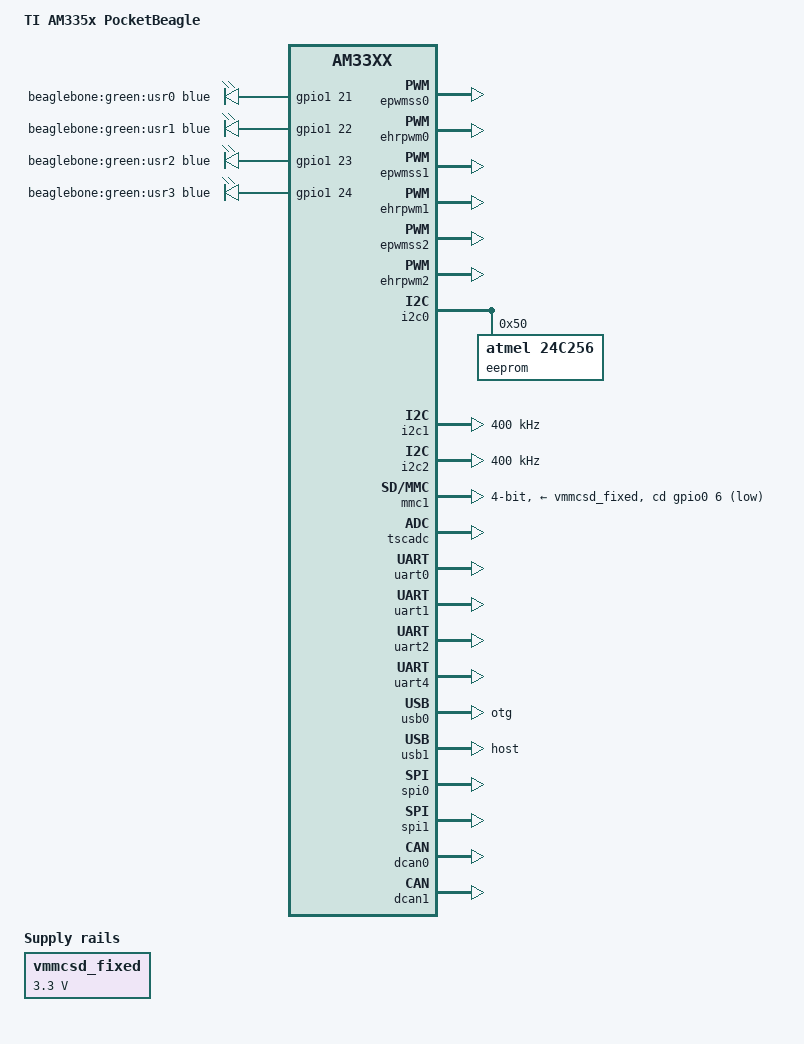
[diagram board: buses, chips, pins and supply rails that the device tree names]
// SPDX-License-Identifier: GPL-2.0
/*
 * Copyright (C) 2012 Texas Instruments Incorporated - https://www.ti.com/
 *
 * Author: Robert Nelson <robertcnelson@gmail.com>
 */
/dts-v1/;

#include "am33xx.dtsi"
#include "am335x-osd335x-common.dtsi"
#include <dt-bindings/leds/common.h>
#include <dt-bindings/board/am335x-bone-pins.h>

/ {
	model = "TI AM335x PocketBeagle";
	compatible = "ti,am335x-pocketbeagle", "ti,am335x-bone", "ti,am33xx";

	chosen {
		stdout-path = &uart0;
		base_dtb = "am335x-pocketbeagle.dts";
		base_dtb_timestamp = __TIMESTAMP__;
	};

	leds {
		pinctrl-names = "default";
		pinctrl-0 = <&usr_leds_pins>;

		compatible = "gpio-leds";

		led-usr0 {
			label = "beaglebone:green:usr0";
			color = <LED_COLOR_ID_BLUE>;
			function = LED_FUNCTION_HEARTBEAT;
			gpios = <&gpio1 21 GPIO_ACTIVE_HIGH>;
			linux,default-trigger = "heartbeat";
			default-state = "off";
		};

		led-usr1 {
			label = "beaglebone:green:usr1";
			color = <LED_COLOR_ID_BLUE>;
			function = LED_FUNCTION_DISK_ACTIVITY;
			gpios = <&gpio1 22 GPIO_ACTIVE_HIGH>;
			linux,default-trigger = "mmc0";
			default-state = "off";
		};

		led-usr2 {
			label = "beaglebone:green:usr2";
			color = <LED_COLOR_ID_BLUE>;
			function = LED_FUNCTION_CPU;
			gpios = <&gpio1 23 GPIO_ACTIVE_HIGH>;
			linux,default-trigger = "cpu0";
			default-state = "off";
		};

		led-usr3 {
			label = "beaglebone:green:usr3";
			color = <LED_COLOR_ID_BLUE>;
			function = LED_FUNCTION_INDICATOR;
			gpios = <&gpio1 24 GPIO_ACTIVE_HIGH>;
			default-state = "off";
		};
	};

	vmmcsd_fixed: fixedregulator0 {
		compatible = "regulator-fixed";
		regulator-name = "vmmcsd_fixed";
		regulator-min-microvolt = <3300000>;
		regulator-max-microvolt = <3300000>;
	};
};

&gpio0 {
	gpio-line-names =
		"NC",
		"NC",
		"P1.08 [SPI0_CLK]",
		"P1.10 [SPI0_MISO]",
		"P1.12 [SPI0_MOSI]",
		"P1.06 [SPI0_CS]",
		"[MMC0_CD]",
		"P2.29 [SPI1_CLK]",
		"[SYSBOOT 12]",
		"[SYSBOOT 13]",
		"[SYSBOOT 14]",
		"[SYSBOOT 15]",
		"P1.26 [I2C2_SDA]",
		"P1.28 [I2C2_SCL]",
		"P2.11 [I2C1_SDA]",
		"P2.09 [I2C1_SCL]",
		"NC",
		"NC",
		"NC",
		"P2.31 [SPI1_CS]",
		"P1.20 [PRU0.16]",
		"NC",
		"NC",
		"P2.03",
		"NC",
		"NC",
		"P1.34",
		"P2.19",
		"NC",
		"NC",
		"P2.05 [UART4_RX]",
		"P2.07 [UART4_TX]";
};

&gpio1 {
	gpio-line-names =
		"NC",
		"NC",
		"NC",
		"NC",
		"NC",
		"NC",
		"NC",
		"NC",
		"NC",
		"P2.25 [SPI1_MOSI]",
		"P1.32 [UART0_RX]",
		"P1.30 [UART0_TX]",
		"P2.24",
		"P2.33",
		"P2.22",
		"P2.18 [PRU0.15i]",
		"NC",
		"NC",
		"P2.01 [PWM1A]",
		"NC",
		"P2.10",
		"[USR LED 0]",
		"[USR LED 1]",
		"[USR LED 2]",
		"[USR LED 3]",
		"P2.06",
		"P2.04",
		"P2.02",
		"P2.08",
		"NC",
		"NC",
		"NC";
};

&gpio2 {
	gpio-line-names =
		"P2.20",
		"P2.17",
		"NC",
		"NC",
		"NC",
		"[EEPROM_WP]",
		"[SYSBOOT 0]",
		"[SYSBOOT 1]",
		"[SYSBOOT 2]",
		"[SYSBOOT 3]",
		"[SYSBOOT 4]",
		"[SYSBOOT 5]",
		"[SYSBOOT 6]",
		"[SYSBOOT 7]",
		"[SYSBOOT 8]",
		"[SYSBOOT 9]",
		"[SYSBOOT 10]",
		"[SYSBOOT 11]",
		"NC",
		"NC",
		"NC",
		"NC",
		"P2.35 [AIN5]",
		"P1.02 [AIN6]",
		"P1.35 [PRU1.10]",
		"P1.04 [PRU1.11]",
		"[MMC0_DAT3]",
		"[MMC0_DAT2]",
		"[MMC0_DAT1]",
		"[MMC0_DAT0]",
		"[MMC0_CLK]",
		"[MMC0_CMD]";
};

&gpio3 {
	gpio-line-names =
		"NC",
		"NC",
		"NC",
		"NC",
		"NC",
		"[I2C0_SDA]",
		"[I2C0_SCL]",
		"[JTAG EMU0]",
		"[JTAG EMU1]",
		"NC",
		"NC",
		"NC",
		"NC",
		"P1.03 [USB1]",
		"P1.36 [PWM0A]",
		"P1.33 [PRU0.1]",
		"P2.32 [PRU0.2]",
		"P2.30 [PRU0.3]",
		"P1.31 [PRU0.4]",
		"P2.34 [PRU0.5]",
		"P2.28 [PRU0.6]",
		"P1.29 [PRU0.7]",
		"NC",
		"NC",
		"NC",
		"NC",
		"NC",
		"NC",
		"NC",
		"NC",
		"NC",
		"NC";
};

&am33xx_pinmux {
//	i2c2_pins: pinmux-i2c2-pins {
//		pinctrl-single,pins = <
//			AM33XX_PADCONF(AM335X_PIN_UART1_RTSN, PIN_INPUT_PULLUP, MUX_MODE3)	/* (D17) uart1_rtsn.I2C2_SCL */
//			AM33XX_PADCONF(AM335X_PIN_UART1_CTSN, PIN_INPUT_PULLUP, MUX_MODE3)	/* (D18) uart1_ctsn.I2C2_SDA */
//		>;
//	};

//	ehrpwm0_pins: pinmux-ehrpwm0-pins {
//		pinctrl-single,pins = <
//			AM33XX_PADCONF(AM335X_PIN_MCASP0_ACLKX, PIN_OUTPUT_PULLDOWN, MUX_MODE1)	/* (A13) mcasp0_aclkx.ehrpwm0A */
//		>;
//	};

//	ehrpwm1_pins: pinmux-ehrpwm1-pins {
//		pinctrl-single,pins = <
//			AM33XX_PADCONF(AM335X_PIN_GPMC_A2, PIN_OUTPUT_PULLDOWN, MUX_MODE6)	/* (U14) gpmc_a2.ehrpwm1A */
//		>;
//	};

	mmc0_pins: pinmux-mmc0-pins {
		pinctrl-single,pins = <
			AM33XX_PADCONF(AM335X_PIN_SPI0_CS1, PIN_INPUT, MUX_MODE7)		/* (C15) spi0_cs1.gpio0[6] */
			AM33XX_PADCONF(AM335X_PIN_MMC0_DAT0, PIN_INPUT_PULLUP, MUX_MODE0)
			AM33XX_PADCONF(AM335X_PIN_MMC0_DAT1, PIN_INPUT_PULLUP, MUX_MODE0)
			AM33XX_PADCONF(AM335X_PIN_MMC0_DAT2, PIN_INPUT_PULLUP, MUX_MODE0)
			AM33XX_PADCONF(AM335X_PIN_MMC0_DAT3, PIN_INPUT_PULLUP, MUX_MODE0)
			AM33XX_PADCONF(AM335X_PIN_MMC0_CMD, PIN_INPUT_PULLUP, MUX_MODE0)
			AM33XX_PADCONF(AM335X_PIN_MMC0_CLK, PIN_INPUT_PULLUP, MUX_MODE0)
		>;
	};

//	spi0_pins: pinmux-spi0-pins {
//		pinctrl-single,pins = <
//			AM33XX_PADCONF(AM335X_PIN_SPI0_SCLK, PIN_INPUT_PULLUP, MUX_MODE0)	/* (A17) spi0_sclk.spi0_sclk */
//			AM33XX_PADCONF(AM335X_PIN_SPI0_D0, PIN_INPUT_PULLUP, MUX_MODE0)	/* (B17) spi0_d0.spi0_d0 */
//			AM33XX_PADCONF(AM335X_PIN_SPI0_D1, PIN_INPUT_PULLUP, MUX_MODE0)	/* (B16) spi0_d1.spi0_d1 */
//			AM33XX_PADCONF(AM335X_PIN_SPI0_CS0, PIN_INPUT_PULLUP, MUX_MODE0)	/* (A16) spi0_cs0.spi0_cs0 */
//		>;
//	};

//	spi1_pins: pinmux-spi1-pins {
//		pinctrl-single,pins = <
//			AM33XX_PADCONF(AM335X_PIN_ECAP0_IN_PWM0_OUT, PIN_INPUT_PULLUP, MUX_MODE4)	/* (C18) eCAP0_in_PWM0_out.spi1_sclk */
//			AM33XX_PADCONF(AM335X_PIN_UART0_CTSN, PIN_INPUT_PULLUP, MUX_MODE4)	/* (E18) uart0_ctsn.spi1_d0 */
//			AM33XX_PADCONF(AM335X_PIN_UART0_RTSN, PIN_INPUT_PULLUP, MUX_MODE4)	/* (E17) uart0_rtsn.spi1_d1 */
//			AM33XX_PADCONF(AM335X_PIN_XDMA_EVENT_INTR0, PIN_INPUT_PULLUP, MUX_MODE4)	/* (A15) xdma_event_intr0.spi1_cs1 */
//		>;
//	};

	usr_leds_pins: pinmux-usr-leds-pins {
		pinctrl-single,pins = <
			AM33XX_PADCONF(AM335X_PIN_GPMC_A5, PIN_OUTPUT, MUX_MODE7)		/* (V15) gpmc_a5.gpio1[21] - USR_LED_0 */
			AM33XX_PADCONF(AM335X_PIN_GPMC_A6, PIN_OUTPUT, MUX_MODE7)		/* (U15) gpmc_a6.gpio1[22] - USR_LED_1 */
			AM33XX_PADCONF(AM335X_PIN_GPMC_A7, PIN_OUTPUT, MUX_MODE7)		/* (T15) gpmc_a7.gpio1[23] - USR_LED_2 */
			AM33XX_PADCONF(AM335X_PIN_GPMC_A8, PIN_OUTPUT, MUX_MODE7)		/* (V16) gpmc_a8.gpio1[24] - USR_LED_3 */
		>;
	};

	uart0_pins: pinmux-uart0-pins {
		pinctrl-single,pins = <
			AM33XX_PADCONF(AM335X_PIN_UART0_RXD, PIN_INPUT_PULLUP, MUX_MODE0)
			AM33XX_PADCONF(AM335X_PIN_UART0_TXD, PIN_OUTPUT_PULLDOWN, MUX_MODE0)
		>;
	};

//	uart4_pins: pinmux-uart4-pins {
//		pinctrl-single,pins = <
//			AM33XX_PADCONF(AM335X_PIN_GPMC_WAIT0, PIN_INPUT_PULLUP, MUX_MODE6)	/* (T17) gpmc_wait0.uart4_rxd */
//			AM33XX_PADCONF(AM335X_PIN_GPMC_WPN, PIN_OUTPUT_PULLDOWN, MUX_MODE6)	/* (U17) gpmc_wpn.uart4_txd */
//		>;
//	};


/* macro: BONE_PIN( <pin>, <mode_name>, <register_value_macro(s)> */
#define BONE_PIN(XX,ZZ,QQ) \
	XX##_##ZZ##_pin: pinmux_##XX##_##ZZ##_pin { pinctrl-single,pins = < QQ >; };

	/************************/
	/* P1 Header */
	/************************/

	/* P1_01                VIN-AC */

	/* P1_02 (ZCZ ball R5) lcd_hsync (gpio2_23) */
	BONE_PIN(P1_02, default, P1_02(PIN_INPUT | MUX_MODE7))
	BONE_PIN(P1_02, gpio, P1_02(PIN_OUTPUT | INPUT_EN | MUX_MODE7))
	BONE_PIN(P1_02, gpio_pu, P1_02(PIN_OUTPUT_PULLUP | INPUT_EN | MUX_MODE7))
	BONE_PIN(P1_02, gpio_pd, P1_02(PIN_OUTPUT_PULLDOWN | INPUT_EN | MUX_MODE7))
	BONE_PIN(P1_02, pruout, P1_02(PIN_OUTPUT_PULLDOWN | INPUT_EN | MUX_MODE5))
	BONE_PIN(P1_02, pruin, P1_02(PIN_INPUT | MUX_MODE6))

	/* P1_03 (ZCZ ball F15)  usb1_vbus_out */

	/* P1_04 (ZCZ ball R6) lcd_ac_bias_en (gpio2_25) */
	BONE_PIN(P1_04, default, P1_04(PIN_OUTPUT_PULLDOWN | INPUT_EN | MUX_MODE7))
	BONE_PIN(P1_04, gpio, P1_04(PIN_OUTPUT | INPUT_EN | MUX_MODE7))
	BONE_PIN(P1_04, gpio_pu, P1_04(PIN_OUTPUT_PULLUP | INPUT_EN | MUX_MODE7))
	BONE_PIN(P1_04, gpio_pd, P1_04(PIN_OUTPUT_PULLDOWN | INPUT_EN | MUX_MODE7))
	BONE_PIN(P1_04, pruout, P1_04(PIN_OUTPUT_PULLDOWN | INPUT_EN | MUX_MODE5))
	BONE_PIN(P1_04, pruin, P1_04(PIN_INPUT | MUX_MODE6))

	/* P1_05 (ZCZ ball T18)  usb1_vbus_in */

	/* P1_06 (ZCZ ball A16) spi0_cs0 (spi0_cs0) */
	BONE_PIN(P1_06, default, P1_06(PIN_OUTPUT_PULLUP | INPUT_EN | MUX_MODE0))
	BONE_PIN(P1_06, gpio, P1_06(PIN_OUTPUT | INPUT_EN | MUX_MODE7))
	BONE_PIN(P1_06, gpio_pu, P1_06(PIN_OUTPUT_PULLUP | INPUT_EN | MUX_MODE7))
	BONE_PIN(P1_06, gpio_pd, P1_06(PIN_OUTPUT_PULLDOWN | INPUT_EN | MUX_MODE7))
	BONE_PIN(P1_06, spi_cs, P1_06(PIN_OUTPUT_PULLUP | INPUT_EN | MUX_MODE0))
	BONE_PIN(P1_06, i2c, P1_06(PIN_OUTPUT_PULLUP | INPUT_EN | MUX_MODE2))
	BONE_PIN(P1_06, pwm, P1_06(PIN_OUTPUT_PULLDOWN | INPUT_EN | MUX_MODE3))
	BONE_PIN(P1_06, pru_uart, P1_06(PIN_OUTPUT_PULLUP | INPUT_EN | MUX_MODE4))

	/* P1_07                VIN-USB */

	/* P1_08 (ZCZ ball A17) spi0_sclk (spi0_sclk) */
	BONE_PIN(P1_08, default, P1_08(PIN_OUTPUT_PULLUP | INPUT_EN | MUX_MODE0))
	BONE_PIN(P1_08, gpio, P1_08(PIN_OUTPUT | INPUT_EN | MUX_MODE7))
	BONE_PIN(P1_08, gpio_pu, P1_08(PIN_OUTPUT_PULLUP | INPUT_EN | MUX_MODE7))
	BONE_PIN(P1_08, gpio_pd, P1_08(PIN_OUTPUT_PULLDOWN | INPUT_EN | MUX_MODE7))
	BONE_PIN(P1_08, spi_sclk, P1_08(PIN_INPUT_PULLUP | MUX_MODE0))
	BONE_PIN(P1_08, uart, P1_08(PIN_OUTPUT_PULLUP | INPUT_EN | MUX_MODE1))
	BONE_PIN(P1_08, i2c, P1_08(PIN_OUTPUT_PULLUP | INPUT_EN | MUX_MODE2))
	BONE_PIN(P1_08, pwm, P1_08(PIN_OUTPUT_PULLDOWN | INPUT_EN | MUX_MODE3))
	BONE_PIN(P1_08, pru_uart, P1_08(PIN_OUTPUT_PULLUP | INPUT_EN | MUX_MODE4))

	/* P1_09 (ZCZ ball R18)  USB1-DN */

	/* P1_10 (ZCZ ball B17) spi0_d0 (spi0_d0) */
	BONE_PIN(P1_10, default, P1_10(PIN_OUTPUT_PULLUP | INPUT_EN | MUX_MODE0))
	BONE_PIN(P1_10, gpio, P1_10(PIN_OUTPUT | INPUT_EN | MUX_MODE7))
	BONE_PIN(P1_10, gpio_pu, P1_10(PIN_OUTPUT_PULLUP | INPUT_EN | MUX_MODE7))
	BONE_PIN(P1_10, gpio_pd, P1_10(PIN_OUTPUT_PULLDOWN | INPUT_EN | MUX_MODE7))
	BONE_PIN(P1_10, spi, P1_10(PIN_INPUT_PULLUP | MUX_MODE0))
	BONE_PIN(P1_10, uart, P1_10(PIN_OUTPUT_PULLUP | INPUT_EN | MUX_MODE1))
	BONE_PIN(P1_10, i2c, P1_10(PIN_OUTPUT_PULLUP | INPUT_EN | MUX_MODE2))
	BONE_PIN(P1_10, pwm, P1_10(PIN_OUTPUT_PULLDOWN | INPUT_EN | MUX_MODE3))
	BONE_PIN(P1_10, pru_uart, P1_10(PIN_OUTPUT_PULLUP | INPUT_EN | MUX_MODE4))

	/* P1_11 (ZCZ ball R17)  USB1-DP */

	/* P1_12 (ZCZ ball B16) spi0_d1 (spi0_d1) */
	BONE_PIN(P1_12, default, P1_12(PIN_OUTPUT_PULLUP | INPUT_EN | MUX_MODE0))
	BONE_PIN(P1_12, gpio, P1_12(PIN_OUTPUT | INPUT_EN | MUX_MODE7))
	BONE_PIN(P1_12, gpio_pu, P1_12(PIN_OUTPUT_PULLUP | INPUT_EN | MUX_MODE7))
	BONE_PIN(P1_12, gpio_pd, P1_12(PIN_OUTPUT_PULLDOWN | INPUT_EN | MUX_MODE7))
	BONE_PIN(P1_12, spi, P1_12(PIN_OUTPUT_PULLUP | INPUT_EN | MUX_MODE0))
	BONE_PIN(P1_12, i2c, P1_12(PIN_OUTPUT_PULLUP | INPUT_EN | MUX_MODE2))
	BONE_PIN(P1_12, pwm, P1_12(PIN_OUTPUT_PULLDOWN | INPUT_EN | MUX_MODE3))
	BONE_PIN(P1_12, pru_uart, P1_12(PIN_OUTPUT_PULLUP | INPUT_EN | MUX_MODE4))

	/* P1_13 (ZCZ ball P17)  USB1-ID */

	/* P1_14                VOUT-3.3V */

	/* P1_15                GND */

	/* P1_16                GND */

	/* P1_17 (ZCZ ball A9)  VREFN */

	/* P1_18 (ZCZ ball B9)  VREFP */

	/* P1_19 (ZCZ ball B6)  AIN0 */

	/* P1_20 (ZCZ ball D14) xdma_event_intr1 (gpio0_20) */
	BONE_PIN(P1_20, default, P1_20(PIN_OUTPUT_PULLDOWN | INPUT_EN | MUX_MODE7))
	BONE_PIN(P1_20, gpio, P1_20(PIN_OUTPUT | INPUT_EN | MUX_MODE7))
	BONE_PIN(P1_20, gpio_pu, P1_20(PIN_OUTPUT_PULLUP | INPUT_EN | MUX_MODE7))
	BONE_PIN(P1_20, gpio_pd, P1_20(PIN_OUTPUT_PULLDOWN | INPUT_EN | MUX_MODE7))
	BONE_PIN(P1_20, pruin, P1_20(PIN_INPUT | MUX_MODE5))

	/* P1_21 (ZCZ ball C7)  AIN1 */

	/* P1_22                GND */

	/* P1_23 (ZCZ ball B7)  AIN2 */

	/* P1_24                VOUT-5V */

	/* P1_25 (ZCZ ball A7)  AIN3 */

	/* P1_26 (ZCZ ball D18) uart1_ctsn (i2c2_sda) */
	BONE_PIN(P1_26, default, P1_26(PIN_OUTPUT_PULLUP | INPUT_EN | MUX_MODE3))
	BONE_PIN(P1_26, gpio, P1_26(PIN_OUTPUT | INPUT_EN | MUX_MODE7))
	BONE_PIN(P1_26, gpio_pu, P1_26(PIN_OUTPUT_PULLUP | INPUT_EN | MUX_MODE7))
	BONE_PIN(P1_26, gpio_pd, P1_26(PIN_OUTPUT_PULLDOWN | INPUT_EN | MUX_MODE7))
	BONE_PIN(P1_26, can, P1_26(PIN_OUTPUT_PULLUP | MUX_MODE2))
	BONE_PIN(P1_26, i2c, P1_26(PIN_OUTPUT_PULLUP | INPUT_EN | MUX_MODE3))
	BONE_PIN(P1_26, spi_cs, P1_26(PIN_OUTPUT_PULLUP | INPUT_EN | MUX_MODE4))
	BONE_PIN(P1_26, pru_uart, P1_26(PIN_OUTPUT_PULLUP | INPUT_EN | MUX_MODE5))

	/* P1_27 (ZCZ ball C8)  AIN4 */

	/* P1_28 (ZCZ ball D17) uart1_rtsn (i2c2_scl) */
	BONE_PIN(P1_28, default, P1_28(PIN_OUTPUT_PULLUP | INPUT_EN | MUX_MODE3))
	BONE_PIN(P1_28, gpio, P1_28(PIN_OUTPUT | INPUT_EN | MUX_MODE7))
	BONE_PIN(P1_28, gpio_pu, P1_28(PIN_OUTPUT_PULLUP | INPUT_EN | MUX_MODE7))
	BONE_PIN(P1_28, gpio_pd, P1_28(PIN_OUTPUT_PULLDOWN | INPUT_EN | MUX_MODE7))
	BONE_PIN(P1_28, can, P1_28(PIN_INPUT_PULLUP | MUX_MODE2))
	BONE_PIN(P1_28, i2c, P1_28(PIN_OUTPUT_PULLUP | INPUT_EN | MUX_MODE3))
	BONE_PIN(P1_28, spi_cs, P1_28(PIN_OUTPUT_PULLUP | INPUT_EN | MUX_MODE4))
	BONE_PIN(P1_28, pru_uart, P1_28(PIN_OUTPUT_PULLUP | INPUT_EN | MUX_MODE5))

	/* P1_29 (ZCZ ball A14) mcasp0_ahclkx (pru0_in7) */
	BONE_PIN(P1_29, default, P1_29(PIN_INPUT | MUX_MODE6))
	BONE_PIN(P1_29, gpio, P1_29(PIN_OUTPUT | INPUT_EN | MUX_MODE7))
	BONE_PIN(P1_29, gpio_pu, P1_29(PIN_OUTPUT_PULLUP | INPUT_EN | MUX_MODE7))
	BONE_PIN(P1_29, gpio_pd, P1_29(PIN_OUTPUT_PULLDOWN | INPUT_EN | MUX_MODE7))
	BONE_PIN(P1_29, eqep, P1_29(PIN_OUTPUT_PULLUP | INPUT_EN | MUX_MODE1))
	BONE_PIN(P1_29, pruout, P1_29(PIN_OUTPUT_PULLDOWN | INPUT_EN | MUX_MODE5))
	BONE_PIN(P1_29, pruin, P1_29(PIN_INPUT | MUX_MODE6))

	/* P1_30 (ZCZ ball E16) uart0_txd (uart0_txd) */
	BONE_PIN(P1_30, default, P1_30(PIN_OUTPUT_PULLUP | INPUT_EN | MUX_MODE0))
	BONE_PIN(P1_30, gpio, P1_30(PIN_OUTPUT | INPUT_EN | MUX_MODE7))
	BONE_PIN(P1_30, gpio_pu, P1_30(PIN_OUTPUT_PULLUP | INPUT_EN | MUX_MODE7))
	BONE_PIN(P1_30, gpio_pd, P1_30(PIN_OUTPUT_PULLDOWN | INPUT_EN | MUX_MODE7))
	BONE_PIN(P1_30, uart, P1_30(PIN_OUTPUT_PULLUP | INPUT_EN | MUX_MODE0))
	BONE_PIN(P1_30, spi_cs, P1_30(PIN_OUTPUT_PULLUP | INPUT_EN | MUX_MODE1))
	BONE_PIN(P1_30, can, P1_30(PIN_INPUT_PULLUP | MUX_MODE2))
	BONE_PIN(P1_30, i2c, P1_30(PIN_OUTPUT_PULLUP | INPUT_EN | MUX_MODE3))
	BONE_PIN(P1_30, pruout, P1_30(PIN_OUTPUT_PULLDOWN | INPUT_EN | MUX_MODE5))
	BONE_PIN(P1_30, pruin, P1_30(PIN_INPUT | MUX_MODE6))

	/* P1_31 (ZCZ ball B12) mcasp0_aclkr (pru0_in4) */
	BONE_PIN(P1_31, default, P1_31(PIN_INPUT | MUX_MODE6))
	BONE_PIN(P1_31, gpio, P1_31(PIN_OUTPUT | INPUT_EN | MUX_MODE7))
	BONE_PIN(P1_31, gpio_pu, P1_31(PIN_OUTPUT_PULLUP | INPUT_EN | MUX_MODE7))
	BONE_PIN(P1_31, gpio_pd, P1_31(PIN_OUTPUT_PULLDOWN | INPUT_EN | MUX_MODE7))
	BONE_PIN(P1_31, eqep, P1_31(PIN_OUTPUT_PULLUP | INPUT_EN | MUX_MODE1))
	BONE_PIN(P1_31, pruout, P1_31(PIN_OUTPUT_PULLDOWN | INPUT_EN | MUX_MODE5))
	BONE_PIN(P1_31, pruin, P1_31(PIN_INPUT | MUX_MODE6))

	/* P1_32 (ZCZ ball E15) uart0_rxd (uart0_rxd) */
	BONE_PIN(P1_32, default, P1_32(PIN_OUTPUT_PULLUP | INPUT_EN | MUX_MODE0))
	BONE_PIN(P1_32, gpio, P1_32(PIN_OUTPUT | INPUT_EN | MUX_MODE7))
	BONE_PIN(P1_32, gpio_pu, P1_32(PIN_OUTPUT_PULLUP | INPUT_EN | MUX_MODE7))
	BONE_PIN(P1_32, gpio_pd, P1_32(PIN_OUTPUT_PULLDOWN | INPUT_EN | MUX_MODE7))
	BONE_PIN(P1_32, uart, P1_32(PIN_OUTPUT_PULLUP | INPUT_EN | MUX_MODE0))
	BONE_PIN(P1_32, spi_cs, P1_32(PIN_OUTPUT_PULLUP | INPUT_EN | MUX_MODE1))
	BONE_PIN(P1_32, can, P1_32(PIN_OUTPUT_PULLUP | MUX_MODE2))
	BONE_PIN(P1_32, i2c, P1_32(PIN_OUTPUT_PULLUP | INPUT_EN | MUX_MODE3))
	BONE_PIN(P1_32, pruout, P1_32(PIN_OUTPUT_PULLDOWN | INPUT_EN | MUX_MODE5))
	BONE_PIN(P1_32, pruin, P1_32(PIN_INPUT | MUX_MODE6))

	/* P1_33 (ZCZ ball B13) mcasp0_fsx (pru0_in1) */
	BONE_PIN(P1_33, default, P1_33(PIN_INPUT | MUX_MODE6))
	BONE_PIN(P1_33, gpio, P1_33(PIN_OUTPUT | INPUT_EN | MUX_MODE7))
	BONE_PIN(P1_33, gpio_pu, P1_33(PIN_OUTPUT_PULLUP | INPUT_EN | MUX_MODE7))
	BONE_PIN(P1_33, gpio_pd, P1_33(PIN_OUTPUT_PULLDOWN | INPUT_EN | MUX_MODE7))
	BONE_PIN(P1_33, pwm, P1_33(PIN_OUTPUT_PULLDOWN | INPUT_EN | MUX_MODE1))
	BONE_PIN(P1_33, spi, P1_33(PIN_INPUT_PULLUP | MUX_MODE3))
	BONE_PIN(P1_33, pruout, P1_33(PIN_OUTPUT_PULLDOWN | INPUT_EN | MUX_MODE5))
	BONE_PIN(P1_33, pruin, P1_33(PIN_INPUT | MUX_MODE6))

	/* P1_34 (ZCZ ball T11) gpmc_ad10 (gpio0_26) */
	BONE_PIN(P1_34, default, P1_34(PIN_OUTPUT_PULLDOWN | INPUT_EN | MUX_MODE7))
	BONE_PIN(P1_34, gpio, P1_34(PIN_OUTPUT | INPUT_EN | MUX_MODE7))
	BONE_PIN(P1_34, gpio_pu, P1_34(PIN_OUTPUT_PULLUP | INPUT_EN | MUX_MODE7))
	BONE_PIN(P1_34, gpio_pd, P1_34(PIN_OUTPUT_PULLDOWN | INPUT_EN | MUX_MODE7))
	BONE_PIN(P1_34, pwm, P1_34(PIN_OUTPUT_PULLDOWN | INPUT_EN | MUX_MODE4))

	/* P1_35 (ZCZ ball V5) lcd_pclk (pru1_in10) */
	BONE_PIN(P1_35, default, P1_35(PIN_INPUT | MUX_MODE6))
	BONE_PIN(P1_35, gpio, P1_35(PIN_OUTPUT | INPUT_EN | MUX_MODE7))
	BONE_PIN(P1_35, gpio_pu, P1_35(PIN_OUTPUT_PULLUP | INPUT_EN | MUX_MODE7))
	BONE_PIN(P1_35, gpio_pd, P1_35(PIN_OUTPUT_PULLDOWN | INPUT_EN | MUX_MODE7))
	BONE_PIN(P1_35, pruout, P1_35(PIN_OUTPUT_PULLDOWN | INPUT_EN | MUX_MODE5))
	BONE_PIN(P1_35, pruin, P1_35(PIN_INPUT | MUX_MODE6))

	/* P1_36 (ZCZ ball A13) mcasp0_aclkx (ehrpwm0a) */
	BONE_PIN(P1_36, default, P1_36(PIN_OUTPUT_PULLDOWN | INPUT_EN | MUX_MODE1))
	BONE_PIN(P1_36, gpio, P1_36(PIN_OUTPUT | INPUT_EN | MUX_MODE7))
	BONE_PIN(P1_36, gpio_pu, P1_36(PIN_OUTPUT_PULLUP | INPUT_EN | MUX_MODE7))
	BONE_PIN(P1_36, gpio_pd, P1_36(PIN_OUTPUT_PULLDOWN | INPUT_EN | MUX_MODE7))
	BONE_PIN(P1_36, pwm, P1_36(PIN_OUTPUT_PULLDOWN | INPUT_EN | MUX_MODE1))
	BONE_PIN(P1_36, spi_sclk, P1_36(PIN_INPUT_PULLUP | MUX_MODE3))
	BONE_PIN(P1_36, pruout, P1_36(PIN_OUTPUT_PULLDOWN | INPUT_EN | MUX_MODE5))
	BONE_PIN(P1_36, pruin, P1_36(PIN_INPUT | MUX_MODE6))


	/************************/
	/* P2 Header */
	/************************/

	/* P2_01 (ZCZ ball U14) gpmc_a2 (ehrpwm1a) */
	BONE_PIN(P2_01, default, P2_01(PIN_OUTPUT_PULLDOWN | INPUT_EN | MUX_MODE6))
	BONE_PIN(P2_01, gpio, P2_01(PIN_OUTPUT | INPUT_EN | MUX_MODE7))
	BONE_PIN(P2_01, gpio_pu, P2_01(PIN_OUTPUT_PULLUP | INPUT_EN | MUX_MODE7))
	BONE_PIN(P2_01, gpio_pd, P2_01(PIN_OUTPUT_PULLDOWN | INPUT_EN | MUX_MODE7))
	BONE_PIN(P2_01, pwm, P2_01(PIN_OUTPUT_PULLDOWN | INPUT_EN | MUX_MODE6))

	/* P2_02 (ZCZ ball V17) gpmc_a11 (gpio1_27) */
	BONE_PIN(P2_02, default, P2_02(PIN_OUTPUT_PULLDOWN | INPUT_EN | MUX_MODE7))
	BONE_PIN(P2_02, gpio, P2_02(PIN_OUTPUT | INPUT_EN | MUX_MODE7))
	BONE_PIN(P2_02, gpio_pu, P2_02(PIN_OUTPUT_PULLUP | INPUT_EN | MUX_MODE7))
	BONE_PIN(P2_02, gpio_pd, P2_02(PIN_OUTPUT_PULLDOWN | INPUT_EN | MUX_MODE7))

	/* P2_03 (ZCZ ball T10) gpmc_ad9 (gpio0_23) */
	BONE_PIN(P2_03, default, P2_03(PIN_OUTPUT_PULLDOWN | INPUT_EN | MUX_MODE7))
	BONE_PIN(P2_03, gpio, P2_03(PIN_OUTPUT | INPUT_EN | MUX_MODE7))
	BONE_PIN(P2_03, gpio_pu, P2_03(PIN_OUTPUT_PULLUP | INPUT_EN | MUX_MODE7))
	BONE_PIN(P2_03, gpio_pd, P2_03(PIN_OUTPUT_PULLDOWN | INPUT_EN | MUX_MODE7))
	BONE_PIN(P2_03, pwm, P2_03(PIN_OUTPUT_PULLDOWN | INPUT_EN | MUX_MODE4))

	/* P2_04 (ZCZ ball T16) gpmc_a10 (gpio1_26) */
	BONE_PIN(P2_04, default, P2_04(PIN_OUTPUT_PULLDOWN | INPUT_EN | MUX_MODE7))
	BONE_PIN(P2_04, gpio, P2_04(PIN_OUTPUT | INPUT_EN | MUX_MODE7))
	BONE_PIN(P2_04, gpio_pu, P2_04(PIN_OUTPUT_PULLUP | INPUT_EN | MUX_MODE7))
	BONE_PIN(P2_04, gpio_pd, P2_04(PIN_OUTPUT_PULLDOWN | INPUT_EN | MUX_MODE7))

	/* P2_05 (ZCZ ball T17) gpmc_wait0 (uart4_rxd) */
	BONE_PIN(P2_05, default, P2_05(PIN_OUTPUT_PULLUP | INPUT_EN | MUX_MODE6))
	BONE_PIN(P2_05, gpio, P2_05(PIN_OUTPUT | INPUT_EN | MUX_MODE7))
	BONE_PIN(P2_05, gpio_pu, P2_05(PIN_OUTPUT_PULLUP | INPUT_EN | MUX_MODE7))
	BONE_PIN(P2_05, gpio_pd, P2_05(PIN_OUTPUT_PULLDOWN | INPUT_EN | MUX_MODE7))
	BONE_PIN(P2_05, uart, P2_05(PIN_OUTPUT_PULLUP | INPUT_EN | MUX_MODE6))

	/* P2_06 (ZCZ ball U16) gpmc_a9 (gpio1_25) */
	BONE_PIN(P2_06, default, P2_06(PIN_OUTPUT_PULLDOWN | INPUT_EN | MUX_MODE7))
	BONE_PIN(P2_06, gpio, P2_06(PIN_OUTPUT | INPUT_EN | MUX_MODE7))
	BONE_PIN(P2_06, gpio_pu, P2_06(PIN_OUTPUT_PULLUP | INPUT_EN | MUX_MODE7))
	BONE_PIN(P2_06, gpio_pd, P2_06(PIN_OUTPUT_PULLDOWN | INPUT_EN | MUX_MODE7))

	/* P2_07 (ZCZ ball U17) gpmc_wpn (uart4_txd) */
	BONE_PIN(P2_07, default, P2_07(PIN_OUTPUT_PULLUP | INPUT_EN | MUX_MODE6))
	BONE_PIN(P2_07, gpio, P2_07(PIN_OUTPUT | INPUT_EN | MUX_MODE7))
	BONE_PIN(P2_07, gpio_pu, P2_07(PIN_OUTPUT_PULLUP | INPUT_EN | MUX_MODE7))
	BONE_PIN(P2_07, gpio_pd, P2_07(PIN_OUTPUT_PULLDOWN | INPUT_EN | MUX_MODE7))
	BONE_PIN(P2_07, uart, P2_07(PIN_OUTPUT_PULLUP | INPUT_EN | MUX_MODE6))

	/* P2_08 (ZCZ ball U18) gpmc_be1n (gpio1_28) */
	BONE_PIN(P2_08, default, P2_08(PIN_OUTPUT_PULLUP | INPUT_EN | MUX_MODE7))
	BONE_PIN(P2_08, gpio, P2_08(PIN_OUTPUT | INPUT_EN | MUX_MODE7))
	BONE_PIN(P2_08, gpio_pu, P2_08(PIN_OUTPUT_PULLUP | INPUT_EN | MUX_MODE7))
	BONE_PIN(P2_08, gpio_pd, P2_08(PIN_OUTPUT_PULLDOWN | INPUT_EN | MUX_MODE7))

	/* P2_09 (ZCZ ball D15) uart1_txd (i2c1_scl) */
	BONE_PIN(P2_09, default, P2_09(PIN_OUTPUT_PULLUP | INPUT_EN | MUX_MODE3))
	BONE_PIN(P2_09, gpio, P2_09(PIN_OUTPUT | INPUT_EN | MUX_MODE7))
	BONE_PIN(P2_09, gpio_pu, P2_09(PIN_OUTPUT_PULLUP | INPUT_EN | MUX_MODE7))
	BONE_PIN(P2_09, gpio_pd, P2_09(PIN_OUTPUT_PULLDOWN | INPUT_EN | MUX_MODE7))
	BONE_PIN(P2_09, uart, P2_09(PIN_OUTPUT_PULLUP | INPUT_EN | MUX_MODE0))
	BONE_PIN(P2_09, can, P2_09(PIN_INPUT_PULLUP | MUX_MODE2))
	BONE_PIN(P2_09, i2c, P2_09(PIN_OUTPUT_PULLUP | INPUT_EN | MUX_MODE3))
	BONE_PIN(P2_09, pru_uart, P2_09(PIN_OUTPUT_PULLUP | INPUT_EN | MUX_MODE5))
	BONE_PIN(P2_09, pruin, P2_09(PIN_INPUT | MUX_MODE6))

	/* P2_10 (ZCZ ball R14) gpmc_a4 (gpio1_20) */
	BONE_PIN(P2_10, default, P2_10(PIN_OUTPUT_PULLDOWN | INPUT_EN | MUX_MODE7))
	BONE_PIN(P2_10, gpio, P2_10(PIN_OUTPUT | INPUT_EN | MUX_MODE7))
	BONE_PIN(P2_10, gpio_pu, P2_10(PIN_OUTPUT_PULLUP | INPUT_EN | MUX_MODE7))
	BONE_PIN(P2_10, gpio_pd, P2_10(PIN_OUTPUT_PULLDOWN | INPUT_EN | MUX_MODE7))
	BONE_PIN(P2_10, eqep, P2_10(PIN_OUTPUT_PULLUP | INPUT_EN | MUX_MODE6))

	/* P2_11 (ZCZ ball D16) uart1_rxd (i2c1_sda) */
	BONE_PIN(P2_11, default, P2_11(PIN_OUTPUT_PULLUP | INPUT_EN | MUX_MODE3))
	BONE_PIN(P2_11, gpio, P2_11(PIN_OUTPUT | INPUT_EN | MUX_MODE7))
	BONE_PIN(P2_11, gpio_pu, P2_11(PIN_OUTPUT_PULLUP | INPUT_EN | MUX_MODE7))
	BONE_PIN(P2_11, gpio_pd, P2_11(PIN_OUTPUT_PULLDOWN | INPUT_EN | MUX_MODE7))
	BONE_PIN(P2_11, uart, P2_11(PIN_OUTPUT_PULLUP | INPUT_EN | MUX_MODE0))
	BONE_PIN(P2_11, can, P2_11(PIN_OUTPUT_PULLUP | MUX_MODE2))
	BONE_PIN(P2_11, i2c, P2_11(PIN_OUTPUT_PULLUP | INPUT_EN | MUX_MODE3))
	BONE_PIN(P2_11, pru_uart, P2_11(PIN_OUTPUT_PULLUP | INPUT_EN | MUX_MODE5))
	BONE_PIN(P2_11, pruin, P2_11(PIN_INPUT | MUX_MODE6))

	/* P2_12                POWER_BUTTON */

	/* P2_13                VOUT-5V */

	/* P2_14                BAT-VIN */

	/* P2_15                GND */

	/* P2_16                BAT-TEMP */

	/* P2_17 (ZCZ ball V12) gpmc_clk (gpio2_1) */
	BONE_PIN(P2_17, default, P2_17(PIN_OUTPUT_PULLDOWN | INPUT_EN | MUX_MODE7))
	BONE_PIN(P2_17, gpio, P2_17(PIN_OUTPUT | INPUT_EN | MUX_MODE7))
	BONE_PIN(P2_17, gpio_pu, P2_17(PIN_OUTPUT_PULLUP | INPUT_EN | MUX_MODE7))
	BONE_PIN(P2_17, gpio_pd, P2_17(PIN_OUTPUT_PULLDOWN | INPUT_EN | MUX_MODE7))

	/* P2_18 (ZCZ ball U13) gpmc_ad15 (gpio1_15) */
	BONE_PIN(P2_18, default, P2_18(PIN_OUTPUT_PULLDOWN | INPUT_EN | MUX_MODE7))
	BONE_PIN(P2_18, gpio, P2_18(PIN_OUTPUT | INPUT_EN | MUX_MODE7))
	BONE_PIN(P2_18, gpio_pu, P2_18(PIN_OUTPUT_PULLUP | INPUT_EN | MUX_MODE7))
	BONE_PIN(P2_18, gpio_pd, P2_18(PIN_OUTPUT_PULLDOWN | INPUT_EN | MUX_MODE7))
	BONE_PIN(P2_18, eqep, P2_18(PIN_OUTPUT_PULLUP | INPUT_EN | MUX_MODE4))
	BONE_PIN(P2_18, pru_ecap_pwm, P2_18(PIN_OUTPUT_PULLDOWN | INPUT_EN | MUX_MODE5))
	BONE_PIN(P2_18, pruin, P2_18(PIN_INPUT | MUX_MODE6))

	/* P2_19 (ZCZ ball U12) gpmc_ad11 (gpio0_27) */
	BONE_PIN(P2_19, default, P2_19(PIN_OUTPUT_PULLDOWN | INPUT_EN | MUX_MODE7))
	BONE_PIN(P2_19, gpio, P2_19(PIN_OUTPUT | INPUT_EN | MUX_MODE7))
	BONE_PIN(P2_19, gpio_pu, P2_19(PIN_OUTPUT_PULLUP | INPUT_EN | MUX_MODE7))
	BONE_PIN(P2_19, gpio_pd, P2_19(PIN_OUTPUT_PULLDOWN | INPUT_EN | MUX_MODE7))
	BONE_PIN(P2_19, pwm, P2_19(PIN_OUTPUT_PULLDOWN | INPUT_EN | MUX_MODE4))

	/* P2_20 (ZCZ ball T13) gpmc_csn3 (gpio2_0) */
	BONE_PIN(P2_20, default, P2_20(PIN_OUTPUT_PULLUP | INPUT_EN | MUX_MODE7))
	BONE_PIN(P2_20, gpio, P2_20(PIN_OUTPUT | INPUT_EN | MUX_MODE7))
	BONE_PIN(P2_20, gpio_pu, P2_20(PIN_OUTPUT_PULLUP | INPUT_EN | MUX_MODE7))
	BONE_PIN(P2_20, gpio_pd, P2_20(PIN_OUTPUT_PULLDOWN | INPUT_EN | MUX_MODE7))

	/* P2_21                GND */

	/* P2_22 (ZCZ ball V13) gpmc_ad14 (gpio1_14) */
	BONE_PIN(P2_22, default, P2_22(PIN_OUTPUT_PULLDOWN | INPUT_EN | MUX_MODE7))
	BONE_PIN(P2_22, gpio, P2_22(PIN_OUTPUT | INPUT_EN | MUX_MODE7))
	BONE_PIN(P2_22, gpio_pu, P2_22(PIN_OUTPUT_PULLUP | INPUT_EN | MUX_MODE7))
	BONE_PIN(P2_22, gpio_pd, P2_22(PIN_OUTPUT_PULLDOWN | INPUT_EN | MUX_MODE7))
	BONE_PIN(P2_22, eqep, P2_22(PIN_OUTPUT_PULLUP | INPUT_EN | MUX_MODE4))
	BONE_PIN(P2_22, pruin, P2_22(PIN_INPUT | MUX_MODE6))

	/* P2_23                VOUT-3.3V */

	/* P2_24 (ZCZ ball T12) gpmc_ad12 (gpio1_12) */
	BONE_PIN(P2_24, default, P2_24(PIN_OUTPUT_PULLDOWN | INPUT_EN | MUX_MODE7))
	BONE_PIN(P2_24, gpio, P2_24(PIN_OUTPUT | INPUT_EN | MUX_MODE7))
	BONE_PIN(P2_24, gpio_pu, P2_24(PIN_OUTPUT_PULLUP | INPUT_EN | MUX_MODE7))
	BONE_PIN(P2_24, gpio_pd, P2_24(PIN_OUTPUT_PULLDOWN | INPUT_EN | MUX_MODE7))
	BONE_PIN(P2_24, eqep, P2_24(PIN_OUTPUT_PULLUP | INPUT_EN | MUX_MODE4))
	BONE_PIN(P2_24, pruout, P2_24(PIN_OUTPUT_PULLDOWN | INPUT_EN | MUX_MODE6))

	/* P2_25 (ZCZ ball E17) uart0_rtsn (spi1_d1) */
	BONE_PIN(P2_25, default, P2_25(PIN_OUTPUT_PULLUP | INPUT_EN | MUX_MODE4))
	BONE_PIN(P2_25, gpio, P2_25(PIN_OUTPUT | INPUT_EN | MUX_MODE7))
	BONE_PIN(P2_25, gpio_pu, P2_25(PIN_OUTPUT_PULLUP | INPUT_EN | MUX_MODE7))
	BONE_PIN(P2_25, gpio_pd, P2_25(PIN_OUTPUT_PULLDOWN | INPUT_EN | MUX_MODE7))
	BONE_PIN(P2_25, uart, P2_25(PIN_OUTPUT_PULLUP | INPUT_EN | MUX_MODE1))
	BONE_PIN(P2_25, can, P2_25(PIN_INPUT_PULLUP | MUX_MODE2))
	BONE_PIN(P2_25, i2c, P2_25(PIN_OUTPUT_PULLUP | INPUT_EN | MUX_MODE3))
	BONE_PIN(P2_25, spi, P2_25(PIN_OUTPUT_PULLUP | INPUT_EN | MUX_MODE4))
	BONE_PIN(P2_25, spi_cs, P2_25(PIN_OUTPUT_PULLUP | INPUT_EN | MUX_MODE5))

	/* P2_26                RESET# */

	/* P2_27 (ZCZ ball E18) uart0_ctsn (spi1_d0) */
	BONE_PIN(P2_27, default, P2_27(PIN_OUTPUT_PULLUP | INPUT_EN | MUX_MODE4))
	BONE_PIN(P2_27, gpio, P2_27(PIN_OUTPUT | INPUT_EN | MUX_MODE7))
	BONE_PIN(P2_27, gpio_pu, P2_27(PIN_OUTPUT_PULLUP | INPUT_EN | MUX_MODE7))
	BONE_PIN(P2_27, gpio_pd, P2_27(PIN_OUTPUT_PULLDOWN | INPUT_EN | MUX_MODE7))
	BONE_PIN(P2_27, uart, P2_27(PIN_OUTPUT_PULLUP | INPUT_EN | MUX_MODE1))
	BONE_PIN(P2_27, can, P2_27(PIN_OUTPUT_PULLUP | MUX_MODE2))
	BONE_PIN(P2_27, i2c, P2_27(PIN_OUTPUT_PULLUP | INPUT_EN | MUX_MODE3))
	BONE_PIN(P2_27, spi, P2_27(PIN_INPUT_PULLUP | MUX_MODE4))

	/* P2_28 (ZCZ ball D13) mcasp0_axr1 (pru0_in6) */
	BONE_PIN(P2_28, default, P2_28(PIN_INPUT | MUX_MODE6))
	BONE_PIN(P2_28, gpio, P2_28(PIN_OUTPUT | INPUT_EN | MUX_MODE7))
	BONE_PIN(P2_28, gpio_pu, P2_28(PIN_OUTPUT_PULLUP | INPUT_EN | MUX_MODE7))
	BONE_PIN(P2_28, gpio_pd, P2_28(PIN_OUTPUT_PULLDOWN | INPUT_EN | MUX_MODE7))
	BONE_PIN(P2_28, eqep, P2_28(PIN_OUTPUT_PULLUP | INPUT_EN | MUX_MODE1))
	BONE_PIN(P2_28, pruout, P2_28(PIN_OUTPUT_PULLDOWN | INPUT_EN | MUX_MODE5))
	BONE_PIN(P2_28, pruin, P2_28(PIN_INPUT | MUX_MODE6))

	/* P2_29 (ZCZ ball C18) eCAP0_in_PWM0_out (spi1_sclk) */
	BONE_PIN(P2_29, default, P2_29(PIN_OUTPUT_PULLUP | INPUT_EN | MUX_MODE4))
	BONE_PIN(P2_29, gpio, P2_29(PIN_OUTPUT | INPUT_EN | MUX_MODE7))
	BONE_PIN(P2_29, gpio_pu, P2_29(PIN_OUTPUT_PULLUP | INPUT_EN | MUX_MODE7))
	BONE_PIN(P2_29, gpio_pd, P2_29(PIN_OUTPUT_PULLDOWN | INPUT_EN | MUX_MODE7))
	BONE_PIN(P2_29, pwm, P2_29(PIN_OUTPUT_PULLDOWN | INPUT_EN | MUX_MODE0))
	BONE_PIN(P2_29, uart, P2_29(PIN_OUTPUT_PULLUP | INPUT_EN | MUX_MODE1))
	BONE_PIN(P2_29, spi_cs, P2_29(PIN_OUTPUT_PULLUP | INPUT_EN | MUX_MODE2))
	BONE_PIN(P2_29, pru_ecap_pwm, P2_29(PIN_OUTPUT_PULLDOWN | INPUT_EN | MUX_MODE3))
	BONE_PIN(P2_29, spi_sclk, P2_29(PIN_INPUT_PULLUP | MUX_MODE4))

	/* P2_30 (ZCZ ball C12) mcasp0_ahclkr (pru0_in3) */
	BONE_PIN(P2_30, default, P2_30(PIN_INPUT | MUX_MODE6))
	BONE_PIN(P2_30, gpio, P2_30(PIN_OUTPUT | INPUT_EN | MUX_MODE7))
	BONE_PIN(P2_30, gpio_pu, P2_30(PIN_OUTPUT_PULLUP | INPUT_EN | MUX_MODE7))
	BONE_PIN(P2_30, gpio_pd, P2_30(PIN_OUTPUT_PULLDOWN | INPUT_EN | MUX_MODE7))
	BONE_PIN(P2_30, pwm, P2_30(PIN_OUTPUT_PULLDOWN | INPUT_EN | MUX_MODE1))
	BONE_PIN(P2_30, spi_cs, P2_30(PIN_OUTPUT_PULLUP | INPUT_EN | MUX_MODE3))
	BONE_PIN(P2_30, pruout, P2_30(PIN_OUTPUT_PULLDOWN | INPUT_EN | MUX_MODE5))
	BONE_PIN(P2_30, pruin, P2_30(PIN_INPUT | MUX_MODE6))

	/* P2_31 (ZCZ ball A15) xdma_event_intr0 (spi1_cs1) */
	BONE_PIN(P2_31, default, P2_31(PIN_OUTPUT_PULLUP | INPUT_EN | MUX_MODE4))
	BONE_PIN(P2_31, gpio, P2_31(PIN_OUTPUT | INPUT_EN | MUX_MODE7))
	BONE_PIN(P2_31, gpio_pu, P2_31(PIN_OUTPUT_PULLUP | INPUT_EN | MUX_MODE7))
	BONE_PIN(P2_31, gpio_pd, P2_31(PIN_OUTPUT_PULLDOWN | INPUT_EN | MUX_MODE7))
	BONE_PIN(P2_31, spi_cs, P2_31(PIN_OUTPUT_PULLUP | INPUT_EN | MUX_MODE4))
	BONE_PIN(P2_31, pruin, P2_31(PIN_INPUT | MUX_MODE5))

	/* P2_32 (ZCZ ball D12) mcasp0_axr0 (pru0_in2) */
	BONE_PIN(P2_32, default, P2_32(PIN_INPUT | MUX_MODE6))
	BONE_PIN(P2_32, gpio, P2_32(PIN_OUTPUT | INPUT_EN | MUX_MODE7))
	BONE_PIN(P2_32, gpio_pu, P2_32(PIN_OUTPUT_PULLUP | INPUT_EN | MUX_MODE7))
	BONE_PIN(P2_32, gpio_pd, P2_32(PIN_OUTPUT_PULLDOWN | INPUT_EN | MUX_MODE7))
	BONE_PIN(P2_32, pwm, P2_32(PIN_OUTPUT_PULLDOWN | INPUT_EN | MUX_MODE1))
	BONE_PIN(P2_32, spi, P2_32(PIN_OUTPUT_PULLUP | INPUT_EN | MUX_MODE3))
	BONE_PIN(P2_32, pruout, P2_32(PIN_OUTPUT_PULLDOWN | INPUT_EN | MUX_MODE5))
	BONE_PIN(P2_32, pruin, P2_32(PIN_INPUT | MUX_MODE6))

	/* P2_33 (ZCZ ball R12) gpmc_ad13 (gpio1_13) */
	BONE_PIN(P2_33, default, P2_33(PIN_OUTPUT_PULLDOWN | INPUT_EN | MUX_MODE7))
	BONE_PIN(P2_33, gpio, P2_33(PIN_OUTPUT | INPUT_EN | MUX_MODE7))
	BONE_PIN(P2_33, gpio_pu, P2_33(PIN_OUTPUT_PULLUP | INPUT_EN | MUX_MODE7))
	BONE_PIN(P2_33, gpio_pd, P2_33(PIN_OUTPUT_PULLDOWN | INPUT_EN | MUX_MODE7))
	BONE_PIN(P2_33, eqep, P2_33(PIN_OUTPUT_PULLUP | INPUT_EN | MUX_MODE4))
	BONE_PIN(P2_33, pruout, P2_33(PIN_OUTPUT_PULLDOWN | INPUT_EN | MUX_MODE6))

	/* P2_34 (ZCZ ball C13) mcasp0_fsr (pru0_in5) */
	BONE_PIN(P2_34, default, P2_34(PIN_INPUT | MUX_MODE6))
	BONE_PIN(P2_34, gpio, P2_34(PIN_OUTPUT | INPUT_EN | MUX_MODE7))
	BONE_PIN(P2_34, gpio_pu, P2_34(PIN_OUTPUT_PULLUP | INPUT_EN | MUX_MODE7))
	BONE_PIN(P2_34, gpio_pd, P2_34(PIN_OUTPUT_PULLDOWN | INPUT_EN | MUX_MODE7))
	BONE_PIN(P2_34, eqep, P2_34(PIN_OUTPUT_PULLUP | INPUT_EN | MUX_MODE1))
	BONE_PIN(P2_34, pruout, P2_34(PIN_OUTPUT_PULLDOWN | INPUT_EN | MUX_MODE5))
	BONE_PIN(P2_34, pruin, P2_34(PIN_INPUT | MUX_MODE6))

	/* P2_35 (ZCZ ball U5) lcd_vsync (gpio2_22) */
	BONE_PIN(P2_35, default, P2_35(PIN_INPUT | MUX_MODE7))
	BONE_PIN(P2_35, gpio, P2_35(PIN_OUTPUT | INPUT_EN | MUX_MODE7))
	BONE_PIN(P2_35, gpio_pu, P2_35(PIN_OUTPUT_PULLUP | INPUT_EN | MUX_MODE7))
	BONE_PIN(P2_35, gpio_pd, P2_35(PIN_OUTPUT_PULLDOWN | INPUT_EN | MUX_MODE7))
	BONE_PIN(P2_35, pruout, P2_35(PIN_OUTPUT_PULLDOWN | INPUT_EN | MUX_MODE5))
	BONE_PIN(P2_35, pruin, P2_35(PIN_INPUT | MUX_MODE6))

	/* P2_36 (ZCZ ball C9)  AIN7 */
};

&epwmss0 {
	status = "okay";
};

&ehrpwm0 {
	status = "okay";
	pinctrl-names = "default";
	//pinctrl-0 = <&ehrpwm0_pins>;
	pinctrl-0 = <>;
};

&epwmss1 {
	status = "okay";
};

&ehrpwm1 {
	status = "okay";
	pinctrl-names = "default";
	//pinctrl-0 = <&ehrpwm1_pins>;
	pinctrl-0 = <>;
};

&epwmss2 {
	status = "okay";
};

&ehrpwm2 {
	status = "okay";
	pinctrl-names = "default";
	pinctrl-0 = <>;
};

&i2c0 {
	eeprom: eeprom@50 {
		compatible = "atmel,24c256";
		reg = <0x50>;
	};
};

&i2c1 {
	pinctrl-names = "default";
	pinctrl-0 = <>;

	status = "okay";
	clock-frequency = <400000>;
};

&i2c2 {
	pinctrl-names = "default";
//	pinctrl-0 = <&i2c2_pins>;
	pinctrl-0 = <>;

	status = "okay";
	clock-frequency = <400000>;
};

&mmc1 {
	status = "okay";
	vmmc-supply = <&vmmcsd_fixed>;
	bus-width = <4>;
	pinctrl-names = "default";
	pinctrl-0 = <&mmc0_pins>;
	cd-gpios = <&gpio0 6 GPIO_ACTIVE_LOW>;
};

&rtc {
	system-power-controller;
};

&tscadc {
	status = "okay";
	adc {
		ti,adc-channels = <0 1 2 3 4 5 6 7>;
		ti,chan-step-avg = <16 16 16 16 16 16 16 16>;
		ti,chan-step-opendelay = <0x98 0x98 0x98 0x98 0x98 0x98 0x98 0x98>;
		ti,chan-step-sampledelay = <0x0 0x0 0x0 0x0 0x0 0x0 0x0 0x0>;
	};
};

&uart0 {
	pinctrl-names = "default";
	//pinctrl-0 = <&uart0_pins>;
	pinctrl-0 = <>;

	status = "okay";
};

&uart1 {
	pinctrl-names = "default";
	pinctrl-0 = <>;

	status = "okay";
};

&uart2 {
	pinctrl-names = "default";
	pinctrl-0 = <>;

	status = "okay";
};

&uart4 {
	pinctrl-names = "default";
	//pinctrl-0 = <&uart4_pins>;
	pinctrl-0 = <>;

	status = "okay";
};

&usb0 {
	dr_mode = "otg";
};

&usb1 {
	dr_mode = "host";
};

&spi0 {
	#address-cells = <1>;
	#size-cells = <0>;
	status = "okay";

	channel@0 {
		#address-cells = <1>;
		#size-cells = <0>;
		compatible = "rohm,dh2228fv";
		symlink = "bone/spi/0.0";
		reg = <0>;
		spi-max-frequency = <24000000>;
	};

	channel@1 {
		#address-cells = <1>;
		#size-cells = <0>;
		compatible = "rohm,dh2228fv";
		symlink = "bone/spi/0.1";
		reg = <1>;
		spi-max-frequency = <24000000>;
		status = "disabled";
	};
};

&spi1 {
	#address-cells = <1>;
	#size-cells = <0>;
	status = "okay";

	channel@0 {
		#address-cells = <1>;
		#size-cells = <0>;
		compatible = "rohm,dh2228fv";
		symlink = "bone/spi/1.0";
		reg = <0>;
		spi-max-frequency = <24000000>;
	};

	channel@1 {
		#address-cells = <1>;
		#size-cells = <0>;
		compatible = "rohm,dh2228fv";
		symlink = "bone/spi/1.1";
		reg = <1>;
		spi-max-frequency = <24000000>;
	};
};

&dcan0 {
	status = "okay";
	pinctrl-names = "default";
	pinctrl-0 = <>;
};

&dcan1 {
	status = "okay";
	pinctrl-names = "default";
	pinctrl-0 = <>;
};

&ocp {
	/************************/
	/* P1 Header */
	/************************/

	/* P1_01                VIN-AC */

	/* P1_02 (ZCZ ball R5) gpio */
	P1_02_pinmux {
		compatible = "bone-pinmux-helper";
		status = "okay";
		pinctrl-names = "default", "gpio", "gpio_pu", "gpio_pd", "pruout", "pruin";
		pinctrl-0 = <&P1_02_default_pin>;
		pinctrl-1 = <&P1_02_gpio_pin>;
		pinctrl-2 = <&P1_02_gpio_pu_pin>;
		pinctrl-3 = <&P1_02_gpio_pd_pin>;
		pinctrl-4 = <&P1_02_pruout_pin>;
		pinctrl-5 = <&P1_02_pruin_pin>;
	};

	/* P1_03 (ZCZ ball F15)  usb1_vbus_out */

	/* P1_04 (ZCZ ball R6) */
	P1_04_pinmux {
		compatible = "bone-pinmux-helper";
		status = "okay";
		pinctrl-names = "default", "gpio", "gpio_pu", "gpio_pd", "pruout", "pruin";
		pinctrl-0 = <&P1_04_default_pin>;
		pinctrl-1 = <&P1_04_gpio_pin>;
		pinctrl-2 = <&P1_04_gpio_pu_pin>;
		pinctrl-3 = <&P1_04_gpio_pd_pin>;
		pinctrl-4 = <&P1_04_pruout_pin>;
		pinctrl-5 = <&P1_04_pruin_pin>;
	};

	/* P1_05 (ZCZ ball T18)  usb1_vbus_in */

	/* P1_06 (ZCZ ball A16) spi_cs */
	P1_06_pinmux {
		compatible = "bone-pinmux-helper";
		status = "okay";
		pinctrl-names = "default", "gpio", "gpio_pu", "gpio_pd", "spi_cs", "i2c", "pwm", "pru_uart";
		pinctrl-0 = <&P1_06_default_pin>;
		pinctrl-1 = <&P1_06_gpio_pin>;
		pinctrl-2 = <&P1_06_gpio_pu_pin>;
		pinctrl-3 = <&P1_06_gpio_pd_pin>;
		pinctrl-4 = <&P1_06_spi_cs_pin>;
		pinctrl-5 = <&P1_06_i2c_pin>;
		pinctrl-6 = <&P1_06_pwm_pin>;
		pinctrl-7 = <&P1_06_pru_uart_pin>;
	};

	/* P1_07                VIN-USB */

	/* P1_08 (ZCZ ball A17) spi_sclk */
	P1_08_pinmux {
		compatible = "bone-pinmux-helper";
		status = "okay";
		pinctrl-names = "default", "gpio", "gpio_pu", "gpio_pd", "spi_sclk", "uart", "i2c", "pwm", "pru_uart";
		pinctrl-0 = <&P1_08_default_pin>;
		pinctrl-1 = <&P1_08_gpio_pin>;
		pinctrl-2 = <&P1_08_gpio_pu_pin>;
		pinctrl-3 = <&P1_08_gpio_pd_pin>;
		pinctrl-4 = <&P1_08_spi_sclk_pin>;
		pinctrl-5 = <&P1_08_uart_pin>;
		pinctrl-6 = <&P1_08_i2c_pin>;
		pinctrl-7 = <&P1_08_pwm_pin>;
		pinctrl-8 = <&P1_08_pru_uart_pin>;
	};

	/* P1_09 (ZCZ ball R18)  USB1-DN */

	/* P1_10 (ZCZ ball B17) spi */
	P1_10_pinmux {
		compatible = "bone-pinmux-helper";
		status = "okay";
		pinctrl-names = "default", "gpio", "gpio_pu", "gpio_pd", "spi", "uart", "i2c", "pwm", "pru_uart";
		pinctrl-0 = <&P1_10_default_pin>;
		pinctrl-1 = <&P1_10_gpio_pin>;
		pinctrl-2 = <&P1_10_gpio_pu_pin>;
		pinctrl-3 = <&P1_10_gpio_pd_pin>;
		pinctrl-4 = <&P1_10_spi_pin>;
		pinctrl-5 = <&P1_10_uart_pin>;
		pinctrl-6 = <&P1_10_i2c_pin>;
		pinctrl-7 = <&P1_10_pwm_pin>;
		pinctrl-8 = <&P1_10_pru_uart_pin>;
	};

	/* P1_11 (ZCZ ball R17)  USB1-DP */

	/* P1_12 (ZCZ ball B16) spi */
	P1_12_pinmux {
		compatible = "bone-pinmux-helper";
		status = "okay";
		pinctrl-names = "default", "gpio", "gpio_pu", "gpio_pd", "spi", "i2c", "pwm", "pru_uart";
		pinctrl-0 = <&P1_12_default_pin>;
		pinctrl-1 = <&P1_12_gpio_pin>;
		pinctrl-2 = <&P1_12_gpio_pu_pin>;
		pinctrl-3 = <&P1_12_gpio_pd_pin>;
		pinctrl-4 = <&P1_12_spi_pin>;
		pinctrl-5 = <&P1_12_i2c_pin>;
		pinctrl-6 = <&P1_12_pwm_pin>;
		pinctrl-7 = <&P1_12_pru_uart_pin>;
	};

	/* P1_13 (ZCZ ball P17)  USB1-ID */

	/* P1_14                VOUT-3.3V */

	/* P1_15                GND */

	/* P1_16                GND */

	/* P1_17 (ZCZ ball A9)  VREFN */

	/* P1_18 (ZCZ ball B9)  VREFP */

	/* P1_19 (ZCZ ball B6)  AIN0 */

	/* P1_20 (ZCZ ball D14) */
	P1_20_pinmux {
		compatible = "bone-pinmux-helper";
		status = "okay";
		pinctrl-names = "default", "gpio", "gpio_pu", "gpio_pd", "pruin";
		pinctrl-0 = <&P1_20_default_pin>;
		pinctrl-1 = <&P1_20_gpio_pin>;
		pinctrl-2 = <&P1_20_gpio_pu_pin>;
		pinctrl-3 = <&P1_20_gpio_pd_pin>;
		pinctrl-4 = <&P1_20_pruin_pin>;
	};

	/* P1_21 (ZCZ ball C7)  AIN1 */

	/* P1_22                GND */

	/* P1_23 (ZCZ ball B7)  AIN2 */

	/* P1_24                VOUT-5V */

	/* P1_25 (ZCZ ball A7)  AIN3 */

	/* P1_26 (ZCZ ball D18) i2c */
	P1_26_pinmux {
		compatible = "bone-pinmux-helper";
		status = "okay";
		pinctrl-names = "default", "gpio", "gpio_pu", "gpio_pd", "spi_cs", "can", "i2c", "pru_uart";
		pinctrl-0 = <&P1_26_default_pin>;
		pinctrl-1 = <&P1_26_gpio_pin>;
		pinctrl-2 = <&P1_26_gpio_pu_pin>;
		pinctrl-3 = <&P1_26_gpio_pd_pin>;
		pinctrl-4 = <&P1_26_spi_cs_pin>;
		pinctrl-5 = <&P1_26_can_pin>;
		pinctrl-6 = <&P1_26_i2c_pin>;
		pinctrl-7 = <&P1_26_pru_uart_pin>;
	};

	/* P1_27 (ZCZ ball C8)  AIN4 */

	/* P1_28 (ZCZ ball D17) i2c */
	P1_28_pinmux {
		compatible = "bone-pinmux-helper";
		status = "okay";
		pinctrl-names = "default", "gpio", "gpio_pu", "gpio_pd", "spi_cs", "can", "i2c", "pru_uart";
		pinctrl-0 = <&P1_28_default_pin>;
		pinctrl-1 = <&P1_28_gpio_pin>;
		pinctrl-2 = <&P1_28_gpio_pu_pin>;
		pinctrl-3 = <&P1_28_gpio_pd_pin>;
		pinctrl-4 = <&P1_28_spi_cs_pin>;
		pinctrl-5 = <&P1_28_can_pin>;
		pinctrl-6 = <&P1_28_i2c_pin>;
		pinctrl-7 = <&P1_28_pru_uart_pin>;
	};

	/* P1_29 (ZCZ ball A14) pruin */
	P1_29_pinmux {
		compatible = "bone-pinmux-helper";
		status = "okay";
		pinctrl-names = "default", "gpio", "gpio_pu", "gpio_pd", "eqep", "pruout", "pruin";
		pinctrl-0 = <&P1_29_default_pin>;
		pinctrl-1 = <&P1_29_gpio_pin>;
		pinctrl-2 = <&P1_29_gpio_pu_pin>;
		pinctrl-3 = <&P1_29_gpio_pd_pin>;
		pinctrl-4 = <&P1_29_eqep_pin>;
		pinctrl-5 = <&P1_29_pruout_pin>;
		pinctrl-6 = <&P1_29_pruin_pin>;
	};

	/* P1_30 (ZCZ ball E16) uart */
	P1_30_pinmux {
		compatible = "bone-pinmux-helper";
		status = "okay";
		pinctrl-names = "default", "gpio", "gpio_pu", "gpio_pd", "spi_cs", "uart", "can", "i2c", "pruout", "pruin";
		pinctrl-0 = <&P1_30_default_pin>;
		pinctrl-1 = <&P1_30_gpio_pin>;
		pinctrl-2 = <&P1_30_gpio_pu_pin>;
		pinctrl-3 = <&P1_30_gpio_pd_pin>;
		pinctrl-4 = <&P1_30_spi_cs_pin>;
		pinctrl-5 = <&P1_30_uart_pin>;
		pinctrl-6 = <&P1_30_can_pin>;
		pinctrl-7 = <&P1_30_i2c_pin>;
		pinctrl-8 = <&P1_30_pruout_pin>;
		pinctrl-9 = <&P1_30_pruin_pin>;
	};

	/* P1_31 (ZCZ ball B12) pruin */
	P1_31_pinmux {
		compatible = "bone-pinmux-helper";
		status = "okay";
		pinctrl-names = "default", "gpio", "gpio_pu", "gpio_pd", "eqep", "pruout", "pruin";
		pinctrl-0 = <&P1_31_default_pin>;
		pinctrl-1 = <&P1_31_gpio_pin>;
		pinctrl-2 = <&P1_31_gpio_pu_pin>;
		pinctrl-3 = <&P1_31_gpio_pd_pin>;
		pinctrl-4 = <&P1_31_eqep_pin>;
		pinctrl-5 = <&P1_31_pruout_pin>;
		pinctrl-6 = <&P1_31_pruin_pin>;
	};

	/* P1_32 (ZCZ ball E15) uart */
	P1_32_pinmux {
		compatible = "bone-pinmux-helper";
		status = "okay";
		pinctrl-names = "default", "gpio", "gpio_pu", "gpio_pd", "spi_cs", "uart", "can", "i2c", "pruout", "pruin";
		pinctrl-0 = <&P1_32_default_pin>;
		pinctrl-1 = <&P1_32_gpio_pin>;
		pinctrl-2 = <&P1_32_gpio_pu_pin>;
		pinctrl-3 = <&P1_32_gpio_pd_pin>;
		pinctrl-4 = <&P1_32_spi_cs_pin>;
		pinctrl-5 = <&P1_32_uart_pin>;
		pinctrl-6 = <&P1_32_can_pin>;
		pinctrl-7 = <&P1_32_i2c_pin>;
		pinctrl-8 = <&P1_32_pruout_pin>;
		pinctrl-9 = <&P1_32_pruin_pin>;
	};

	/* P1_33 (ZCZ ball B13) pruin */
	P1_33_pinmux {
		compatible = "bone-pinmux-helper";
		status = "okay";
		pinctrl-names = "default", "gpio", "gpio_pu", "gpio_pd", "spi", "pwm", "pruout", "pruin";
		pinctrl-0 = <&P1_33_default_pin>;
		pinctrl-1 = <&P1_33_gpio_pin>;
		pinctrl-2 = <&P1_33_gpio_pu_pin>;
		pinctrl-3 = <&P1_33_gpio_pd_pin>;
		pinctrl-4 = <&P1_33_spi_pin>;
		pinctrl-5 = <&P1_33_pwm_pin>;
		pinctrl-6 = <&P1_33_pruout_pin>;
		pinctrl-7 = <&P1_33_pruin_pin>;
	};

	/* P1_34 (ZCZ ball T11) */
	P1_34_pinmux {
		compatible = "bone-pinmux-helper";
		status = "okay";
		pinctrl-names = "default", "gpio", "gpio_pu", "gpio_pd", "pwm";
		pinctrl-0 = <&P1_34_default_pin>;
		pinctrl-1 = <&P1_34_gpio_pin>;
		pinctrl-2 = <&P1_34_gpio_pu_pin>;
		pinctrl-3 = <&P1_34_gpio_pd_pin>;
		pinctrl-4 = <&P1_34_pwm_pin>;
	};

	/* P1_35 (ZCZ ball V5) pruin */
	P1_35_pinmux {
		compatible = "bone-pinmux-helper";
		status = "okay";
		pinctrl-names = "default", "gpio", "gpio_pu", "gpio_pd", "pruout", "pruin";
		pinctrl-0 = <&P1_35_default_pin>;
		pinctrl-1 = <&P1_35_gpio_pin>;
		pinctrl-2 = <&P1_35_gpio_pu_pin>;
		pinctrl-3 = <&P1_35_gpio_pd_pin>;
		pinctrl-4 = <&P1_35_pruout_pin>;
		pinctrl-5 = <&P1_35_pruin_pin>;
	};

	/* P1_36 (ZCZ ball A13) pwm */
	P1_36_pinmux {
		compatible = "bone-pinmux-helper";
		status = "okay";
		pinctrl-names = "default", "gpio", "gpio_pu", "gpio_pd", "spi_sclk", "pwm", "pruout", "pruin";
		pinctrl-0 = <&P1_36_default_pin>;
		pinctrl-1 = <&P1_36_gpio_pin>;
		pinctrl-2 = <&P1_36_gpio_pu_pin>;
		pinctrl-3 = <&P1_36_gpio_pd_pin>;
		pinctrl-4 = <&P1_36_spi_sclk_pin>;
		pinctrl-5 = <&P1_36_pwm_pin>;
		pinctrl-6 = <&P1_36_pruout_pin>;
		pinctrl-7 = <&P1_36_pruin_pin>;
	};


	/************************/
	/* P2 Header */
	/************************/

	/* P2_01 (ZCZ ball U14) pwm */
	P2_01_pinmux {
		compatible = "bone-pinmux-helper";
		status = "okay";
		pinctrl-names = "default", "gpio", "gpio_pu", "gpio_pd", "pwm";
		pinctrl-0 = <&P2_01_default_pin>;
		pinctrl-1 = <&P2_01_gpio_pin>;
		pinctrl-2 = <&P2_01_gpio_pu_pin>;
		pinctrl-3 = <&P2_01_gpio_pd_pin>;
		pinctrl-4 = <&P2_01_pwm_pin>;
	};

	/* P2_02 (ZCZ ball V17) */
	P2_02_pinmux {
		compatible = "bone-pinmux-helper";
		status = "okay";
		pinctrl-names = "default", "gpio", "gpio_pu", "gpio_pd";
		pinctrl-0 = <&P2_02_default_pin>;
		pinctrl-1 = <&P2_02_gpio_pin>;
		pinctrl-2 = <&P2_02_gpio_pu_pin>;
		pinctrl-3 = <&P2_02_gpio_pd_pin>;
	};

	/* P2_03 (ZCZ ball T10) */
	P2_03_pinmux {
		compatible = "bone-pinmux-helper";
		status = "okay";
		pinctrl-names = "default", "gpio", "gpio_pu", "gpio_pd", "pwm";
		pinctrl-0 = <&P2_03_default_pin>;
		pinctrl-1 = <&P2_03_gpio_pin>;
		pinctrl-2 = <&P2_03_gpio_pu_pin>;
		pinctrl-3 = <&P2_03_gpio_pd_pin>;
		pinctrl-4 = <&P2_03_pwm_pin>;
	};

	/* P2_04 (ZCZ ball T16) */
	P2_04_pinmux {
		compatible = "bone-pinmux-helper";
		status = "okay";
		pinctrl-names = "default", "gpio", "gpio_pu", "gpio_pd";
		pinctrl-0 = <&P2_04_default_pin>;
		pinctrl-1 = <&P2_04_gpio_pin>;
		pinctrl-2 = <&P2_04_gpio_pu_pin>;
		pinctrl-3 = <&P2_04_gpio_pd_pin>;
	};

	/* P2_05 (ZCZ ball T17) uart */
	P2_05_pinmux {
		compatible = "bone-pinmux-helper";
		status = "okay";
		pinctrl-names = "default", "gpio", "gpio_pu", "gpio_pd", "uart";
		pinctrl-0 = <&P2_05_default_pin>;
		pinctrl-1 = <&P2_05_gpio_pin>;
		pinctrl-2 = <&P2_05_gpio_pu_pin>;
		pinctrl-3 = <&P2_05_gpio_pd_pin>;
		pinctrl-4 = <&P2_05_uart_pin>;
	};

	/* P2_06 (ZCZ ball U16) */
	P2_06_pinmux {
		compatible = "bone-pinmux-helper";
		status = "okay";
		pinctrl-names = "default", "gpio", "gpio_pu", "gpio_pd";
		pinctrl-0 = <&P2_06_default_pin>;
		pinctrl-1 = <&P2_06_gpio_pin>;
		pinctrl-2 = <&P2_06_gpio_pu_pin>;
		pinctrl-3 = <&P2_06_gpio_pd_pin>;
	};

	/* P2_07 (ZCZ ball U17) uart */
	P2_07_pinmux {
		compatible = "bone-pinmux-helper";
		status = "okay";
		pinctrl-names = "default", "gpio", "gpio_pu", "gpio_pd", "uart";
		pinctrl-0 = <&P2_07_default_pin>;
		pinctrl-1 = <&P2_07_gpio_pin>;
		pinctrl-2 = <&P2_07_gpio_pu_pin>;
		pinctrl-3 = <&P2_07_gpio_pd_pin>;
		pinctrl-4 = <&P2_07_uart_pin>;
	};

	/* P2_08 (ZCZ ball U18) */
	P2_08_pinmux {
		compatible = "bone-pinmux-helper";
		status = "okay";
		pinctrl-names = "default", "gpio", "gpio_pu", "gpio_pd";
		pinctrl-0 = <&P2_08_default_pin>;
		pinctrl-1 = <&P2_08_gpio_pin>;
		pinctrl-2 = <&P2_08_gpio_pu_pin>;
		pinctrl-3 = <&P2_08_gpio_pd_pin>;
	};

	/* P2_09 (ZCZ ball D15) i2c */
	P2_09_pinmux {
		compatible = "bone-pinmux-helper";
		status = "okay";
		pinctrl-names = "default", "gpio", "gpio_pu", "gpio_pd", "uart", "can", "i2c", "pru_uart", "pruin";
		pinctrl-0 = <&P2_09_default_pin>;
		pinctrl-1 = <&P2_09_gpio_pin>;
		pinctrl-2 = <&P2_09_gpio_pu_pin>;
		pinctrl-3 = <&P2_09_gpio_pd_pin>;
		pinctrl-4 = <&P2_09_uart_pin>;
		pinctrl-5 = <&P2_09_can_pin>;
		pinctrl-6 = <&P2_09_i2c_pin>;
		pinctrl-7 = <&P2_09_pru_uart_pin>;
		pinctrl-8 = <&P2_09_pruin_pin>;
	};

	/* P2_10 (ZCZ ball R14) */
	P2_10_pinmux {
		compatible = "bone-pinmux-helper";
		status = "okay";
		pinctrl-names = "default", "gpio", "gpio_pu", "gpio_pd", "eqep";
		pinctrl-0 = <&P2_10_default_pin>;
		pinctrl-1 = <&P2_10_gpio_pin>;
		pinctrl-2 = <&P2_10_gpio_pu_pin>;
		pinctrl-3 = <&P2_10_gpio_pd_pin>;
		pinctrl-4 = <&P2_10_eqep_pin>;
	};

	/* P2_11 (ZCZ ball D16) i2c */
	P2_11_pinmux {
		compatible = "bone-pinmux-helper";
		status = "okay";
		pinctrl-names = "default", "gpio", "gpio_pu", "gpio_pd", "uart", "can", "i2c", "pru_uart", "pruin";
		pinctrl-0 = <&P2_11_default_pin>;
		pinctrl-1 = <&P2_11_gpio_pin>;
		pinctrl-2 = <&P2_11_gpio_pu_pin>;
		pinctrl-3 = <&P2_11_gpio_pd_pin>;
		pinctrl-4 = <&P2_11_uart_pin>;
		pinctrl-5 = <&P2_11_can_pin>;
		pinctrl-6 = <&P2_11_i2c_pin>;
		pinctrl-7 = <&P2_11_pru_uart_pin>;
		pinctrl-8 = <&P2_11_pruin_pin>;
	};

	/* P2_12                POWER_BUTTON */

	/* P2_13                VOUT-5V */

	/* P2_14                BAT-VIN */

	/* P2_15                GND */

	/* P2_16                BAT-TEMP */

	/* P2_17 (ZCZ ball V12) */
	P2_17_pinmux {
		compatible = "bone-pinmux-helper";
		status = "okay";
		pinctrl-names = "default", "gpio", "gpio_pu", "gpio_pd";
		pinctrl-0 = <&P2_17_default_pin>;
		pinctrl-1 = <&P2_17_gpio_pin>;
		pinctrl-2 = <&P2_17_gpio_pu_pin>;
		pinctrl-3 = <&P2_17_gpio_pd_pin>;
	};

	/* P2_18 (ZCZ ball U13) */
	P2_18_pinmux {
		compatible = "bone-pinmux-helper";
		status = "okay";
		pinctrl-names = "default", "gpio", "gpio_pu", "gpio_pd", "eqep", "pru_ecap_pwm", "pruin";
		pinctrl-0 = <&P2_18_default_pin>;
		pinctrl-1 = <&P2_18_gpio_pin>;
		pinctrl-2 = <&P2_18_gpio_pu_pin>;
		pinctrl-3 = <&P2_18_gpio_pd_pin>;
		pinctrl-4 = <&P2_18_eqep_pin>;
		pinctrl-5 = <&P2_18_pru_ecap_pwm_pin>;
		pinctrl-6 = <&P2_18_pruin_pin>;
	};

	/* P2_19 (ZCZ ball U12) */
	P2_19_pinmux {
		compatible = "bone-pinmux-helper";
		status = "okay";
		pinctrl-names = "default", "gpio", "gpio_pu", "gpio_pd", "pwm";
		pinctrl-0 = <&P2_19_default_pin>;
		pinctrl-1 = <&P2_19_gpio_pin>;
		pinctrl-2 = <&P2_19_gpio_pu_pin>;
		pinctrl-3 = <&P2_19_gpio_pd_pin>;
		pinctrl-4 = <&P2_19_pwm_pin>;
	};

	/* P2_20 (ZCZ ball T13) */
	P2_20_pinmux {
		compatible = "bone-pinmux-helper";
		status = "okay";
		pinctrl-names = "default", "gpio", "gpio_pu", "gpio_pd";
		pinctrl-0 = <&P2_20_default_pin>;
		pinctrl-1 = <&P2_20_gpio_pin>;
		pinctrl-2 = <&P2_20_gpio_pu_pin>;
		pinctrl-3 = <&P2_20_gpio_pd_pin>;
	};

	/* P2_21                GND */

	/* P2_22 (ZCZ ball V13) */
	P2_22_pinmux {
		compatible = "bone-pinmux-helper";
		status = "okay";
		pinctrl-names = "default", "gpio", "gpio_pu", "gpio_pd", "eqep", "pruin";
		pinctrl-0 = <&P2_22_default_pin>;
		pinctrl-1 = <&P2_22_gpio_pin>;
		pinctrl-2 = <&P2_22_gpio_pu_pin>;
		pinctrl-3 = <&P2_22_gpio_pd_pin>;
		pinctrl-4 = <&P2_22_eqep_pin>;
		pinctrl-5 = <&P2_22_pruin_pin>;
	};

	/* P2_23                VOUT-3.3V */

	/* P2_24 (ZCZ ball T12) */
	P2_24_pinmux {
		compatible = "bone-pinmux-helper";
		status = "okay";
		pinctrl-names = "default", "gpio", "gpio_pu", "gpio_pd", "eqep", "pruout";
		pinctrl-0 = <&P2_24_default_pin>;
		pinctrl-1 = <&P2_24_gpio_pin>;
		pinctrl-2 = <&P2_24_gpio_pu_pin>;
		pinctrl-3 = <&P2_24_gpio_pd_pin>;
		pinctrl-4 = <&P2_24_eqep_pin>;
		pinctrl-5 = <&P2_24_pruout_pin>;
	};

	/* P2_25 (ZCZ ball E17) spi */
	P2_25_pinmux {
		compatible = "bone-pinmux-helper";
		status = "okay";
		pinctrl-names = "default", "gpio", "gpio_pu", "gpio_pd", "spi", "spi_cs", "uart", "can", "i2c";
		pinctrl-0 = <&P2_25_default_pin>;
		pinctrl-1 = <&P2_25_gpio_pin>;
		pinctrl-2 = <&P2_25_gpio_pu_pin>;
		pinctrl-3 = <&P2_25_gpio_pd_pin>;
		pinctrl-4 = <&P2_25_spi_pin>;
		pinctrl-5 = <&P2_25_spi_cs_pin>;
		pinctrl-6 = <&P2_25_uart_pin>;
		pinctrl-7 = <&P2_25_can_pin>;
		pinctrl-8 = <&P2_25_i2c_pin>;
	};

	/* P2_26                RESET# */

	/* P2_27 (ZCZ ball E18) spi */
	P2_27_pinmux {
		compatible = "bone-pinmux-helper";
		status = "okay";
		pinctrl-names = "default", "gpio", "gpio_pu", "gpio_pd", "spi", "uart", "can", "i2c";
		pinctrl-0 = <&P2_27_default_pin>;
		pinctrl-1 = <&P2_27_gpio_pin>;
		pinctrl-2 = <&P2_27_gpio_pu_pin>;
		pinctrl-3 = <&P2_27_gpio_pd_pin>;
		pinctrl-4 = <&P2_27_spi_pin>;
		pinctrl-5 = <&P2_27_uart_pin>;
		pinctrl-6 = <&P2_27_can_pin>;
		pinctrl-7 = <&P2_27_i2c_pin>;
	};

	/* P2_28 (ZCZ ball D13) pruin */
	P2_28_pinmux {
		compatible = "bone-pinmux-helper";
		status = "okay";
		pinctrl-names = "default", "gpio", "gpio_pu", "gpio_pd", "eqep", "pruout", "pruin";
		pinctrl-0 = <&P2_28_default_pin>;
		pinctrl-1 = <&P2_28_gpio_pin>;
		pinctrl-2 = <&P2_28_gpio_pu_pin>;
		pinctrl-3 = <&P2_28_gpio_pd_pin>;
		pinctrl-4 = <&P2_28_eqep_pin>;
		pinctrl-5 = <&P2_28_pruout_pin>;
		pinctrl-6 = <&P2_28_pruin_pin>;
	};

	/* P2_29 (ZCZ ball C18) spi_sclk */
	P2_29_pinmux {
		compatible = "bone-pinmux-helper";
		status = "okay";
		pinctrl-names = "default", "gpio", "gpio_pu", "gpio_pd", "spi_cs", "spi_sclk", "uart", "pwm", "pru_ecap_pwm";
		pinctrl-0 = <&P2_29_default_pin>;
		pinctrl-1 = <&P2_29_gpio_pin>;
		pinctrl-2 = <&P2_29_gpio_pu_pin>;
		pinctrl-3 = <&P2_29_gpio_pd_pin>;
		pinctrl-4 = <&P2_29_spi_cs_pin>;
		pinctrl-5 = <&P2_29_spi_sclk_pin>;
		pinctrl-6 = <&P2_29_uart_pin>;
		pinctrl-7 = <&P2_29_pwm_pin>;
		pinctrl-8 = <&P2_29_pru_ecap_pwm_pin>;
	};

	/* P2_30 (ZCZ ball C12) pruin */
	P2_30_pinmux {
		compatible = "bone-pinmux-helper";
		status = "okay";
		pinctrl-names = "default", "gpio", "gpio_pu", "gpio_pd", "spi_cs", "pwm", "pruout", "pruin";
		pinctrl-0 = <&P2_30_default_pin>;
		pinctrl-1 = <&P2_30_gpio_pin>;
		pinctrl-2 = <&P2_30_gpio_pu_pin>;
		pinctrl-3 = <&P2_30_gpio_pd_pin>;
		pinctrl-4 = <&P2_30_spi_cs_pin>;
		pinctrl-5 = <&P2_30_pwm_pin>;
		pinctrl-6 = <&P2_30_pruout_pin>;
		pinctrl-7 = <&P2_30_pruin_pin>;
	};

	/* P2_31 (ZCZ ball A15) spi_cs */
	P2_31_pinmux {
		compatible = "bone-pinmux-helper";
		status = "okay";
		pinctrl-names = "default", "gpio", "gpio_pu", "gpio_pd", "spi_cs", "pruin";
		pinctrl-0 = <&P2_31_default_pin>;
		pinctrl-1 = <&P2_31_gpio_pin>;
		pinctrl-2 = <&P2_31_gpio_pu_pin>;
		pinctrl-3 = <&P2_31_gpio_pd_pin>;
		pinctrl-4 = <&P2_31_spi_cs_pin>;
		pinctrl-5 = <&P2_31_pruin_pin>;
	};

	/* P2_32 (ZCZ ball D12) pruin */
	P2_32_pinmux {
		compatible = "bone-pinmux-helper";
		status = "okay";
		pinctrl-names = "default", "gpio", "gpio_pu", "gpio_pd", "spi", "pwm", "pruout", "pruin";
		pinctrl-0 = <&P2_32_default_pin>;
		pinctrl-1 = <&P2_32_gpio_pin>;
		pinctrl-2 = <&P2_32_gpio_pu_pin>;
		pinctrl-3 = <&P2_32_gpio_pd_pin>;
		pinctrl-4 = <&P2_32_spi_pin>;
		pinctrl-5 = <&P2_32_pwm_pin>;
		pinctrl-6 = <&P2_32_pruout_pin>;
		pinctrl-7 = <&P2_32_pruin_pin>;
	};

	/* P2_33 (ZCZ ball R12) */
	P2_33_pinmux {
		compatible = "bone-pinmux-helper";
		status = "okay";
		pinctrl-names = "default", "gpio", "gpio_pu", "gpio_pd", "eqep", "pruout";
		pinctrl-0 = <&P2_33_default_pin>;
		pinctrl-1 = <&P2_33_gpio_pin>;
		pinctrl-2 = <&P2_33_gpio_pu_pin>;
		pinctrl-3 = <&P2_33_gpio_pd_pin>;
		pinctrl-4 = <&P2_33_eqep_pin>;
		pinctrl-5 = <&P2_33_pruout_pin>;
	};

	/* P2_34 (ZCZ ball C13) pruin */
	P2_34_pinmux {
		compatible = "bone-pinmux-helper";
		status = "okay";
		pinctrl-names = "default", "gpio", "gpio_pu", "gpio_pd", "eqep", "pruout", "pruin";
		pinctrl-0 = <&P2_34_default_pin>;
		pinctrl-1 = <&P2_34_gpio_pin>;
		pinctrl-2 = <&P2_34_gpio_pu_pin>;
		pinctrl-3 = <&P2_34_gpio_pd_pin>;
		pinctrl-4 = <&P2_34_eqep_pin>;
		pinctrl-5 = <&P2_34_pruout_pin>;
		pinctrl-6 = <&P2_34_pruin_pin>;
	};

	/* P2_35 (ZCZ ball U5) gpio */
	P2_35_pinmux {
		compatible = "bone-pinmux-helper";
		status = "okay";
		pinctrl-names = "default", "gpio", "gpio_pu", "gpio_pd", "pruout", "pruin";
		pinctrl-0 = <&P2_35_default_pin>;
		pinctrl-1 = <&P2_35_gpio_pin>;
		pinctrl-2 = <&P2_35_gpio_pu_pin>;
		pinctrl-3 = <&P2_35_gpio_pd_pin>;
		pinctrl-4 = <&P2_35_pruout_pin>;
		pinctrl-5 = <&P2_35_pruin_pin>;
	};

	/* P2_36 (ZCZ ball C9)  AIN7 */

	cape-universal {
		compatible = "gpio-of-helper";
		status = "okay";
		pinctrl-names = "default";
		pinctrl-0 = <>;

		P1_02 {
			gpio-name = "P1_02";
			gpio = <&gpio2 23 0>;
			input;
			dir-changeable;
		};

		P1_04 {
			gpio-name = "P1_04";
			gpio = <&gpio2 25 0>;
			input;
			dir-changeable;
		};

		P1_06 {
			gpio-name = "P1_06";
			gpio = <&gpio0 5 0>;
			input;
			dir-changeable;
		};

		P1_08 {
			gpio-name = "P1_08";
			gpio = <&gpio0 2 0>;
			input;
			dir-changeable;
		};

		P1_10 {
			gpio-name = "P1_10";
			gpio = <&gpio0 3 0>;
			input;
			dir-changeable;
		};

		P1_12 {
			gpio-name = "P1_12";
			gpio = <&gpio0 4 0>;
			input;
			dir-changeable;
		};

		P1_20 {
			gpio-name = "P1_20";
			gpio = <&gpio0 20 0>;
			input;
			dir-changeable;
		};

		P1_26 {
			gpio-name = "P1_26";
			gpio = <&gpio0 12 0>;
			input;
			dir-changeable;
		};

		P1_28 {
			gpio-name = "P1_28";
			gpio = <&gpio0 13 0>;
			input;
			dir-changeable;
		};

		P1_29 {
			gpio-name = "P1_29";
			gpio = <&gpio3 21 0>;
			input;
			dir-changeable;
		};

		P1_30 {
			gpio-name = "P1_30";
			gpio = <&gpio1 11 0>;
			input;
			dir-changeable;
		};

		P1_31 {
			gpio-name = "P1_31";
			gpio = <&gpio3 18 0>;
			input;
			dir-changeable;
		};

		P1_32 {
			gpio-name = "P1_32";
			gpio = <&gpio1 10 0>;
			input;
			dir-changeable;
		};

		P1_33 {
			gpio-name = "P1_33";
			gpio = <&gpio3 15 0>;
			input;
			dir-changeable;
		};

		P1_34 {
			gpio-name = "P1_34";
			gpio = <&gpio0 26 0>;
			input;
			dir-changeable;
		};

		P1_35 {
			gpio-name = "P1_35";
			gpio = <&gpio2 24 0>;
			input;
			dir-changeable;
		};

		P1_36 {
			gpio-name = "P1_36";
			gpio = <&gpio3 14 0>;
			input;
			dir-changeable;
		};

		P2_01 {
			gpio-name = "P2_01";
			gpio = <&gpio1 18 0>;
			input;
			dir-changeable;
		};

		P2_02 {
			gpio-name = "P2_02";
			gpio = <&gpio1 27 0>;
			input;
			dir-changeable;
		};

		P2_03 {
			gpio-name = "P2_03";
			gpio = <&gpio0 23 0>;
			input;
			dir-changeable;
		};

		P2_04 {
			gpio-name = "P2_04";
			gpio = <&gpio1 26 0>;
			input;
			dir-changeable;
		};

		P2_05 {
			gpio-name = "P2_05";
			gpio = <&gpio0 30 0>;
			input;
			dir-changeable;
		};

		P2_06 {
			gpio-name = "P2_06";
			gpio = <&gpio1 25 0>;
			input;
			dir-changeable;
		};

		P2_07 {
			gpio-name = "P2_07";
			gpio = <&gpio0 31 0>;
			input;
			dir-changeable;
		};

		P2_08 {
			gpio-name = "P2_08";
			gpio = <&gpio1 28 0>;
			input;
			dir-changeable;
		};

		P2_09 {
			gpio-name = "P2_09";
			gpio = <&gpio0 15 0>;
			input;
			dir-changeable;
		};

		P2_10 {
			gpio-name = "P2_10";
			gpio = <&gpio1 20 0>;
			input;
			dir-changeable;
		};

		P2_11 {
			gpio-name = "P2_11";
			gpio = <&gpio0 14 0>;
			input;
			dir-changeable;
		};

		P2_17 {
			gpio-name = "P2_17";
			gpio = <&gpio2 1 0>;
			input;
			dir-changeable;
		};

		P2_18 {
			gpio-name = "P2_18";
			gpio = <&gpio1 15 0>;
			input;
			dir-changeable;
		};

		P2_19 {
			gpio-name = "P2_19";
			gpio = <&gpio0 27 0>;
			input;
			dir-changeable;
		};

		P2_20 {
			gpio-name = "P2_20";
			gpio = <&gpio2 0 0>;
			input;
			dir-changeable;
		};

		P2_22 {
			gpio-name = "P2_22";
			gpio = <&gpio1 14 0>;
			input;
			dir-changeable;
		};

		P2_24 {
			gpio-name = "P2_24";
			gpio = <&gpio1 12 0>;
			input;
			dir-changeable;
		};

		P2_25 {
			gpio-name = "P2_25";
			gpio = <&gpio1 9 0>;
			input;
			dir-changeable;
		};

		P2_27 {
			gpio-name = "P2_27";
			gpio = <&gpio1 8 0>;
			input;
			dir-changeable;
		};

		P2_28 {
			gpio-name = "P2_28";
			gpio = <&gpio3 20 0>;
			input;
			dir-changeable;
		};

		P2_29 {
			gpio-name = "P2_29";
			gpio = <&gpio0 7 0>;
			input;
			dir-changeable;
		};

		P2_30 {
			gpio-name = "P2_30";
			gpio = <&gpio3 17 0>;
			input;
			dir-changeable;
		};

		P2_31 {
			gpio-name = "P2_31";
			gpio = <&gpio0 19 0>;
			input;
			dir-changeable;
		};

		P2_32 {
			gpio-name = "P2_32";
			gpio = <&gpio3 16 0>;
			input;
			dir-changeable;
		};

		P2_33 {
			gpio-name = "P2_33";
			gpio = <&gpio1 13 0>;
			input;
			dir-changeable;
		};

		P2_34 {
			gpio-name = "P2_34";
			gpio = <&gpio3 19 0>;
			input;
			dir-changeable;
		};

		P2_35 {
			gpio-name = "P2_35";
			gpio = <&gpio2 22 0>;
			input;
			dir-changeable;
		};

	};
};
